AUTOSAR XML (schema 00046)
package /ComponentTypes
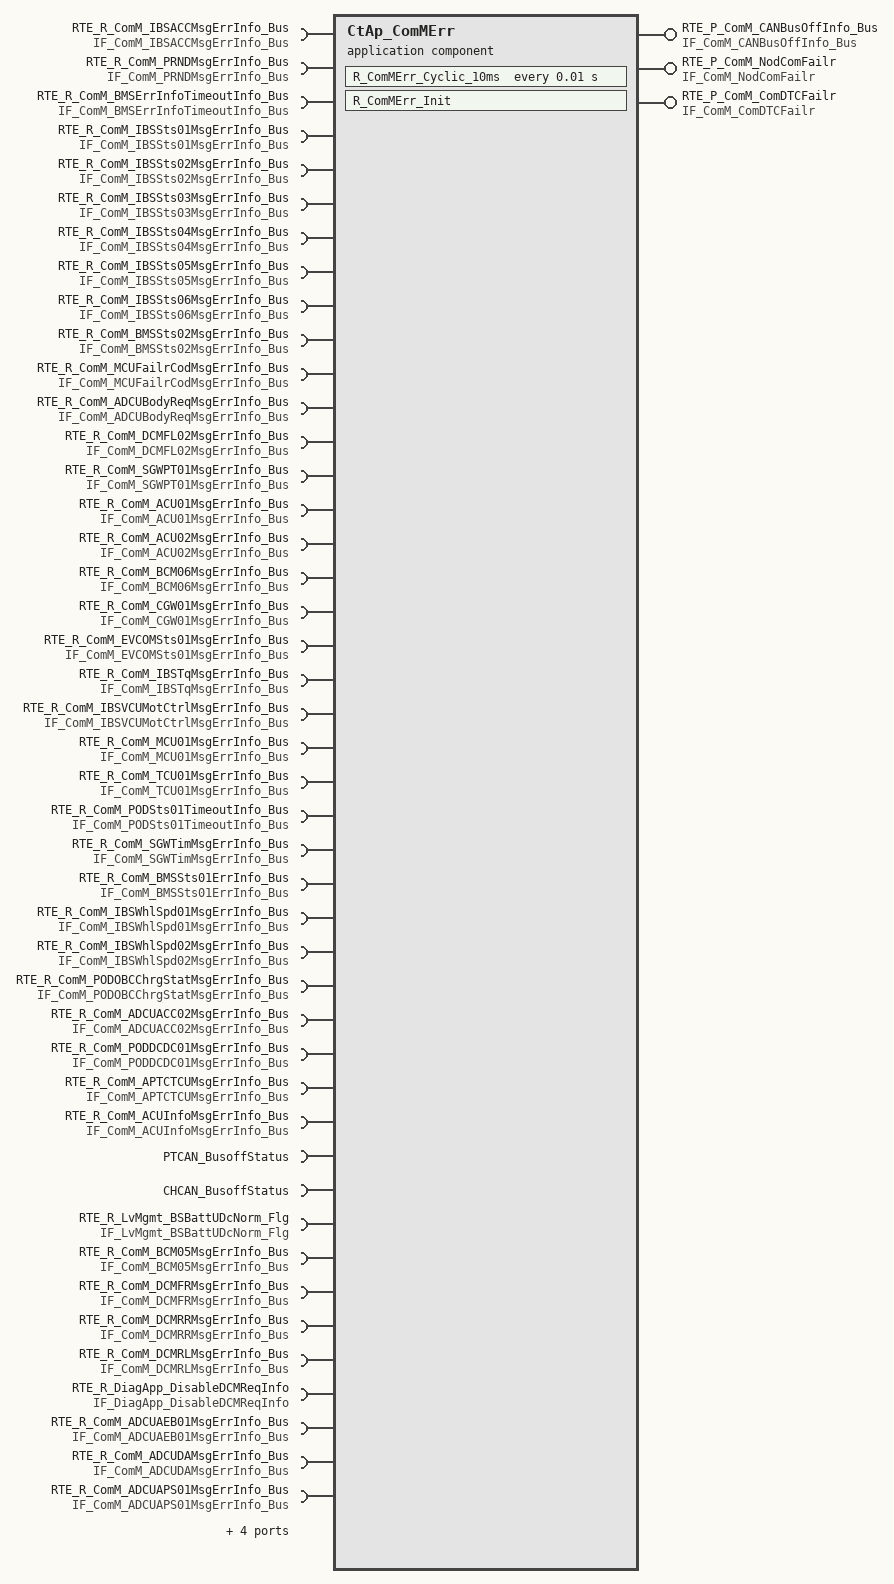
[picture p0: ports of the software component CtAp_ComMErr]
  application sw component type CtAp_ComMErr
    provide port RTE_P_ComM_CANBusOffInfo_Bus: provided-interface=IF_ComM_CANBusOffInfo_Bus
      provided-com-specs:
        data-element=tec_ComM_EPTCANBusOffInfo_Bus, init-value=fields=[ComM_MonStatEPTCANBusOffInfo:0, ComM_MonResEPTCANBusOffInfo:0, ComM_ErrStatEPTCANBusOffInfo:0, ComM_ErrResEPTCANBusOffInfo:0]
        data-element=tec_ComM_CHCANBusOffInfo_Bus, init-value=fields=[ComM_MonStatCHCANBusOffInfo:0, ComM_MonResCHCANBusOffInfo:0, ComM_ErrStatCHCANBusOffInfo:0, ComM_ErrResCHCANBusOffInfo:0]
        data-element=tec_ComM_EPTCANBusOffDTCInfo_Bus, init-value=fields=[ComM_MonStatEPTCANBusOffDTCInfo:0, ComM_MonResEPTCANBusOffDTCInfo:0, ComM_ErrStatEPTCANBusOffDTCInfo:0, ComM_ErrResEPTCANBusOffDTCInfo:0]
        data-element=tec_ComM_CHCANBusOffDTCInfo_Bus, init-value=fields=[ComM_MonStatCHCANBusOffDTCInfo:0, ComM_MonResCHCANBusOffDTCInfo:0, ComM_ErrStatCHCANBusOffDTCInfo:0, ComM_ErrResCHCANBusOffDTCInfo:0]
        data-element=tec_ComM_DCCANBusOffDTCInfo_Bus, init-value=fields=[ComM_MonStatDCCANDTCBusOffInfo:0, ComM_MonResDCCANDTCBusOffInfo:0, ComM_ErrStatDCCANDTCBusOffInfo:0, ComM_ErrResDCCANDTCBusOffInfo:0]
        data-element=tec_ComM_DCCANBusOffInfo_Bus, init-value=fields=[ComM_MonStatDCCANBusOffInfo:0, ComM_MonResDCCANBusOffInfo:0, ComM_ErrStatDCCANBusOffInfo:0, ComM_ErrResDCCANBusOffInfo:0]
    32 x require port:
      RTE_R_ComM_IBSACCMsgErrInfo_Bus: required-interface=IF_ComM_IBSACCMsgErrInfo_Bus
        required-com-specs:
          data-element=tec_ComM_IBSACCCRCDTCInfo_Bus, filter=data-filter-type=ALWAYS, init-value=fields=[ComM_MonStatIBSACCCRCDTCErrorInfo:0, ComM_MonResIBSACCCRCDTCErrorInfo:0, ComM_ErrStatIBSACCCRCDTCErrorInfo:0, ComM_ErrResIBSACCCRCDTCErrorInfo:0]
          data-element=tec_ComM_IBSACCCRCInfo_Bus, filter=data-filter-type=ALWAYS, init-value=fields=[ComM_MonStatIBSACCCRCErrorInfo:0, ComM_MonResIBSACCCRCErrorInfo:0, ComM_ErrStatIBSACCCRCErrorInfo:0, ComM_ErrResIBSACCCRCErrorInfo:0]
          data-element=tec_ComM_IBSACCTimeoutDTCInfo_Bus, filter=data-filter-type=ALWAYS, init-value=fields=[ComM_MonStatIBSACCTimeoutDTCErrorInfo:0, ComM_MonResIBSACCTimeoutDTCErrorInfo:0, ComM_ErrStatIBSACCTimeoutDTCErrorInfo:0, ComM_ErrResIBSACCTimeoutDTCErrorInfo:0]
          data-element=tec_ComM_IBSACCE2ETimeoutInfo_Bus, filter=data-filter-type=ALWAYS, init-value=fields=[ComM_MonStatIBSACCE2ETimeoutInfo:0, ComM_MonResIBSACCE2ETimeoutInfo:0, ComM_ErrStatIBSACCE2ETimeoutInfo:0, ComM_ErrResIBSACCE2ETimeoutInfo:0]
      RTE_R_ComM_PRNDMsgErrInfo_Bus: required-interface=IF_ComM_PRNDMsgErrInfo_Bus
        required-com-specs:
          data-element=tec_ComM_PRNDTimeoutInfo_Bus, filter=data-filter-type=ALWAYS, init-value=fields=[ComM_MonStatPRNDTimeoutInfo:0, ComM_MonResPRNDTimeoutInfo:0, ComM_ErrStatPRNDTimeoutInfo:0, ComM_ErrResPRNDTimeoutInfo:0]
          data-element=tec_ComM_PRNDCRCDTCInfo_Bus, filter=data-filter-type=ALWAYS, init-value=fields=[ComM_MonStatPRNDCRCDTCErrorInfo:0, ComM_MonResPRNDCRCDTCErrorInfo:0, ComM_ErrStatPRNDCRCDTCErrorInfo:0, ComM_ErrResPRNDCRCDTCErrorInfo:0]
          data-element=tec_ComM_PRNDCRCInfo_Bus, filter=data-filter-type=ALWAYS, init-value=fields=[ComM_MonStatPRNDCRCErrorInfo:0, ComM_MonResPRNDCRCErrorInfo:0, ComM_ErrStatPRNDCRCErrorInfo:0, ComM_ErrResPRNDCRCErrorInfo:0]
          data-element=tec_ComM_PRNDTimeoutDTCInfo_Bus, filter=data-filter-type=ALWAYS, init-value=fields=[ComM_MonStatPRNDTimeoutDTCErrorInfo:0, ComM_MonResPRNDTimeoutDTCErrorInfo:0, ComM_ErrStatPRNDTimeoutDTCErrorInfo:0, ComM_ErrResPRNDTimeoutDTCErrorInfo:0]
          data-element=tec_ComM_PRNDE2ETimeoutInfo_Bus, filter=data-filter-type=ALWAYS, init-value=fields=[ComM_MonStatPRNDE2ETimeoutInfo:0, ComM_MonResPRNDE2ETimeoutInfo:0, ComM_ErrStatPRNDE2ETimeoutInfo:0, ComM_ErrResPRNDE2ETimeoutInfo:0]
      RTE_R_ComM_BMSErrInfoTimeoutInfo_Bus: nonqueued-receiver-com-spec{data-element=tec_ComM_BMSErrInfoTimeoutInfo_Bus, filter=data-filter-type=ALWAYS, init-value=fields=[ComM_MonStatBMSErrInfoTimeoutInfo:0, ComM_MonResBMSErrInfoTimeoutInfo:0, ComM_ErrStatBMSErrInfoTimeoutInfo:0, ComM_ErrResBMSErrInfoTimeoutInfo:0]}, required-interface=IF_ComM_BMSErrInfoTimeoutInfo_Bus
      RTE_R_ComM_IBSSts01MsgErrInfo_Bus: required-interface=IF_ComM_IBSSts01MsgErrInfo_Bus
        required-com-specs:
          data-element=tec_ComM_IBSSts01CRCDTCInfo_Bus, filter=data-filter-type=ALWAYS, init-value=fields=[ComM_MonStatIBSSts01CRCDTCErrorInfo:0, ComM_MonResIBSSts01CRCDTCErrorInfo:0, ComM_ErrStatIBSSts01CRCDTCErrorInfo:0, ComM_ErrResIBSSts01CRCDTCErrorInfo:0]
          data-element=tec_ComM_IBSSts01TimeoutDTCInfo_Bus, filter=data-filter-type=ALWAYS, init-value=fields=[ComM_MonStatIBSSts01TimeoutDTCErrorInfo:0, ComM_MonResIBSSts01TimeoutDTCErrorInfo:0, ComM_ErrStatIBSSts01TimeoutDTCErrorInfo:0, ComM_ErrResIBSSts01TimeoutDTCErrorInfo:0]
          data-element=tec_ComM_IBSSts01CRCInfo_Bus, filter=data-filter-type=ALWAYS, init-value=fields=[ComM_MonStatIBSSts01CRCErrorInfo:0, ComM_MonResIBSSts01CRCErrorInfo:0, ComM_ErrStatIBSSts01CRCErrorInfo:0, ComM_ErrResIBSSts01CRCErrorInfo:0]
          data-element=tec_ComM_IBSSts01E2ETimeoutInfo_Bus, filter=data-filter-type=ALWAYS, init-value=fields=[ComM_MonStatIBSSts01E2ETimeoutInfo:0, ComM_MonResIBSSts01E2ETimeoutInfo:0, ComM_ErrStatIBSSts01E2ETimeoutInfo:0, ComM_ErrResIBSSts01E2ETimeoutInfo:0]
      RTE_R_ComM_IBSSts02MsgErrInfo_Bus: required-interface=IF_ComM_IBSSts02MsgErrInfo_Bus
        required-com-specs:
          data-element=tec_ComM_IBSSts02CRCInfo_Bus, filter=data-filter-type=ALWAYS, init-value=fields=[ComM_MonStatIBSSts02CRCErrorInfo:0, ComM_MonResIBSSts02CRCErrorInfo:0, ComM_ErrStatIBSSts02CRCErrorInfo:0, ComM_ErrResIBSSts02CRCErrorInfo:0]
          data-element=tec_ComM_IBSSts02CRCDTCInfo_Bus, filter=data-filter-type=ALWAYS, init-value=fields=[ComM_MonStatIBSSts02CRCDTCErrorInfo:0, ComM_MonResIBSSts02CRCDTCErrorInfo:0, ComM_ErrStatIBSSts02CRCDTCErrorInfo:0, ComM_ErrResIBSSts02CRCDTCErrorInfo:0]
          data-element=tec_ComM_IBSSts02TimeoutDTCInfo_Bus, filter=data-filter-type=ALWAYS, init-value=fields=[ComM_MonStatIBSSts02TimeoutDTCErrorInfo:0, ComM_MonResIBSSts02TimeoutDTCErrorInfo:0, ComM_ErrStatIBSSts02TimeoutDTCErrorInfo:0, ComM_ErrResIBSSts02TimeoutDTCErrorInfo:0]
          data-element=tec_ComM_IBSSts02E2ETimeoutInfo_Bus, filter=data-filter-type=ALWAYS, init-value=fields=[ComM_MonStatIBSSts02E2ETimeoutInfo:0, ComM_MonResIBSSts02E2ETimeoutInfo:0, ComM_ErrStatIBSSts02E2ETimeoutInfo:0, ComM_ErrResIBSSts02E2ETimeoutInfo:0]
      RTE_R_ComM_IBSSts03MsgErrInfo_Bus: required-interface=IF_ComM_IBSSts03MsgErrInfo_Bus
        required-com-specs:
          data-element=tec_ComM_IBSSts03CRCInfo_Bus, filter=data-filter-type=ALWAYS, init-value=fields=[ComM_MonStatIBSSts03CRCErrorInfo:0, ComM_MonResIBSSts03CRCErrorInfo:0, ComM_ErrStatIBSSts03CRCErrorInfo:0, ComM_ErrResIBSSts03CRCErrorInfo:0]
          data-element=tec_ComM_IBSSts03CRCDTCInfo_Bus, filter=data-filter-type=ALWAYS, init-value=fields=[ComM_MonStatIBSSts03CRCDTCErrorInfo:0, ComM_MonResIBSSts03CRCDTCErrorInfo:0, ComM_ErrStatIBSSts03CRCDTCErrorInfo:0, ComM_ErrResIBSSts03CRCDTCErrorInfo:0]
          data-element=tec_ComM_IBSSts03TimeoutDTCInfo_Bus, filter=data-filter-type=ALWAYS, init-value=fields=[ComM_MonStatIBSSts03TimeoutDTCErrorInfo:0, ComM_MonResIBSSts03TimeoutDTCErrorInfo:0, ComM_ErrStatIBSSts03TimeoutDTCErrorInfo:0, ComM_ErrResIBSSts03TimeoutDTCErrorInfo:0]
          data-element=tec_ComM_IBSSts03E2ETimeoutInfo_Bus, filter=data-filter-type=ALWAYS, init-value=fields=[ComM_MonStatIBSSts03E2ETimeoutInfo:0, ComM_MonResIBSSts03E2ETimeoutInfo:0, ComM_ErrStatIBSSts03E2ETimeoutInfo:0, ComM_ErrResIBSSts03E2ETimeoutInfo:0]
      RTE_R_ComM_IBSSts04MsgErrInfo_Bus: required-interface=IF_ComM_IBSSts04MsgErrInfo_Bus
        required-com-specs:
          data-element=tec_ComM_IBSSts04CRCDTCInfo_Bus, filter=data-filter-type=ALWAYS, init-value=fields=[ComM_MonStatIBSSts04CRCDTCErrorInfo:0, ComM_MonResIBSSts04CRCDTCErrorInfo:0, ComM_ErrStatIBSSts04CRCDTCErrorInfo:0, ComM_ErrResIBSSts04CRCDTCErrorInfo:0]
          data-element=tec_ComM_IBSSts04CRCInfo_Bus, filter=data-filter-type=ALWAYS, init-value=fields=[ComM_MonStatIBSSts04CRCErrorInfo:0, ComM_MonResIBSSts04CRCErrorInfo:0, ComM_ErrStatIBSSts04CRCErrorInfo:0, ComM_ErrResIBSSts04CRCErrorInfo:0]
          data-element=tec_ComM_IBSSts04TimeoutDTCInfo_Bus, filter=data-filter-type=ALWAYS, init-value=fields=[ComM_MonStatIBSSts04TimeoutDTCErrorInfo:0, ComM_MonResIBSSts04TimeoutDTCErrorInfo:0, ComM_ErrStatIBSSts04TimeoutDTCErrorInfo:0, ComM_ErrResIBSSts04TimeoutDTCErrorInfo:0]
          data-element=tec_ComM_IBSSts04E2ETimeoutInfo_Bus, filter=data-filter-type=ALWAYS, init-value=fields=[ComM_MonStatIBSSts04E2ETimeoutInfo:0, ComM_MonResIBSSts04E2ETimeoutInfo:0, ComM_ErrStatIBSSts04E2ETimeoutInfo:0, ComM_ErrResIBSSts04E2ETimeoutInfo:0]
      RTE_R_ComM_IBSSts05MsgErrInfo_Bus: required-interface=IF_ComM_IBSSts05MsgErrInfo_Bus
        required-com-specs:
          data-element=tec_ComM_IBSSts05CRCDTCInfo_Bus, filter=data-filter-type=ALWAYS, init-value=fields=[ComM_MonStatIBSSts05CRCDTCErrorInfo:0, ComM_MonResIBSSts05CRCDTCErrorInfo:0, ComM_ErrStatIBSSts05CRCDTCErrorInfo:0, ComM_ErrResIBSSts05CRCDTCErrorInfo:0]
          data-element=tec_ComM_IBSSts05TimeoutDTCInfo_Bus, filter=data-filter-type=ALWAYS, init-value=fields=[ComM_MonStatIBSSts05TimeoutDTCErrorInfo:0, ComM_MonResIBSSts05TimeoutDTCErrorInfo:0, ComM_ErrStatIBSSts05TimeoutDTCErrorInfo:0, ComM_ErrResIBSSts05TimeoutDTCErrorInfo:0]
          data-element=tec_ComM_IBSSts05TimeoutInfo_Bus, filter=data-filter-type=ALWAYS, init-value=fields=[ComM_MonStatIBSSts05TimeoutInfo:0, ComM_MonResIBSSts05TimeoutInfo:0, ComM_ErrStatIBSSts05TimeoutInfo:0, ComM_ErrResIBSSts05TimeoutInfo:0]
          data-element=tec_ComM_IBSSts05CRCInfo_Bus, init-value=fields=[ComM_MonStatIBSSts05CRCErrorInfo:0, ComM_MonResIBSSts05CRCErrorInfo:0, ComM_ErrStatIBSSts05CRCErrorInfo:0, ComM_ErrResIBSSts05CRCErrorInfo:0]
          data-element=tec_ComM_IBSSts05E2ETimeoutInfo_Bus, init-value=fields=[ComM_MonStatIBSSts05E2ETimeoutInfo:0, ComM_MonResIBSSts05E2ETimeoutInfo:0, ComM_ErrStatIBSSts05E2ETimeoutInfo:0, ComM_ErrResIBSSts05E2ETimeoutInfo:0]
      RTE_R_ComM_IBSSts06MsgErrInfo_Bus: required-interface=IF_ComM_IBSSts06MsgErrInfo_Bus
        required-com-specs:
          data-element=tec_ComM_IBSSts06CRCDTCInfo_Bus, filter=data-filter-type=ALWAYS, init-value=fields=[ComM_MonStatIBSSts06CRCDTCErrorInfo:0, ComM_MonResIBSSts06CRCDTCErrorInfo:0, ComM_ErrStatIBSSts06CRCDTCErrorInfo:0, ComM_ErrResIBSSts06CRCDTCErrorInfo:0]
          data-element=tec_ComM_IBSSts06TimeoutDTCInfo_Bus, filter=data-filter-type=ALWAYS, init-value=fields=[ComM_MonStatIBSSts06TimeoutDTCErrorInfo:0, ComM_MonResIBSSts06TimeoutDTCErrorInfo:0, ComM_ErrStatIBSSts06TimeoutDTCErrorInfo:0, ComM_ErrResIBSSts06TimeoutDTCErrorInfo:0]
      RTE_R_ComM_BMSSts02MsgErrInfo_Bus: required-interface=IF_ComM_BMSSts02MsgErrInfo_Bus
        required-com-specs:
          data-element=tec_ComM_BMSSts02TimeoutDTCInfo_Bus, filter=data-filter-type=ALWAYS, init-value=fields=[ComM_MonStatBMSSts02TimeoutDTCErrorInfo:0, ComM_MonResBMSSts02TimeoutDTCErrorInfo:0, ComM_ErrStatBMSSts02TimeoutDTCErrorInfo:0, ComM_ErrResBMSSts02TimeoutDTCErrorInfo:0]
          data-element=tec_ComM_BMSSts02TimeoutInfo_Bus, filter=data-filter-type=ALWAYS, init-value=fields=[ComM_MonStatBMSSts02TimeoutInfo:0, ComM_MonResBMSSts02TimeoutInfo:0, ComM_ErrStatBMSSts02TimeoutInfo:0, ComM_ErrResBMSSts02TimeoutInfo:0]
      RTE_R_ComM_MCUFailrCodMsgErrInfo_Bus: required-interface=IF_ComM_MCUFailrCodMsgErrInfo_Bus
        required-com-specs:
          data-element=tec_ComM_MCUFailrCodCRCDTCInfo_Bus, filter=data-filter-type=ALWAYS, init-value=fields=[ComM_MonStatMCUFailrCodCRCDTCErrorInfo:0, ComM_MonResMCUFailrCodCRCDTCErrorInfo:0, ComM_ErrStatMCUFailrCodCRCDTCErrorInfo:0, ComM_ErrResMCUFailrCodCRCDTCErrorInfo:0]
          data-element=tec_ComM_MCUFailrCodTimeoutDTCInfo_Bus, filter=data-filter-type=ALWAYS, init-value=fields=[ComM_MonStatMCUFailrCodTimeoutDTCErrorInfo:0, ComM_MonResMCUFailrCodTimeoutDTCErrorInfo:0, ComM_ErrStatMCUFailrCodTimeoutDTCErrorInfo:0, ComM_ErrResMCUFailrCodTimeoutDTCErrorInfo:0]
          data-element=tec_ComM_MCUFailrCodCRCInfo_Bus, init-value=fields=[ComM_MonStatMCUFailrCodCRCErrorInfo:0, ComM_MonResMCUFailrCodCRCErrorInfo:0, ComM_ErrStatMCUFailrCodCRCErrorInfo:0, ComM_ErrResMCUFailrCodCRCErrorInfo:0]
          data-element=tec_ComM_MCUFailrCodE2ETimeoutInfo_Bus, init-value=fields=[ComM_MonStatMCUFailrCodE2ETimeouInfo:0, ComM_MonResMCUFailrCodE2ETimeoutInfo:0, ComM_ErrStatMCUFailrCodE2ETimeoutInfo:0, ComM_ErrResMCUFailrCodE2ETimeoutInfo:0]
      RTE_R_ComM_ADCUBodyReqMsgErrInfo_Bus: required-interface=IF_ComM_ADCUBodyReqMsgErrInfo_Bus
        required-com-specs:
          data-element=tec_ComM_ADCUBodyReqCRCDTCInfo_Bus, filter=data-filter-type=ALWAYS, init-value=fields=[ComM_MonStatADCUBodyReqCRCDTCErrorInfo:0, ComM_MonResADCUBodyReqCRCDTCErrorInfo:0, ComM_ErrStatADCUBodyReqCRCDTCErrorInfo:0, ComM_ErrResADCUBodyReqCRCDTCErrorInfo:0]
          data-element=tec_ComM_ADCUBodyReqTimeoutDTCInfo_Bus, filter=data-filter-type=ALWAYS, init-value=fields=[ComM_MonStatADCUBodyReqTimeoutDTCErrorInfo:0, ComM_MonResADCUBodyReqTimeoutDTCErrorInfo:0, ComM_ErrStatADCUBodyReqTimeoutDTCErrorInfo:0, ComM_ErrResADCUBodyReqTimeoutDTCErrorInfo:0]
      RTE_R_ComM_DCMFL02MsgErrInfo_Bus: required-interface=IF_ComM_DCMFL02MsgErrInfo_Bus
        required-com-specs:
          data-element=tec_ComM_DCMFL02CRCDTCInfo_Bus, filter=data-filter-type=ALWAYS, init-value=fields=[ComM_MonStatDCMFL02CRCDTCErrorInfo:0, ComM_MonResDCMFL02CRCDTCErrorInfo:0, ComM_ErrStatDCMFL02CRCDTCErrorInfo:0, ComM_ErrResDCMFL02CRCDTCErrorInfo:0]
          data-element=tec_ComM_DCMFL02TimeoutDTCInfo_Bus, filter=data-filter-type=ALWAYS, init-value=fields=[ComM_MonStatDCMFL02TimeoutDTCErrorInfo:0, ComM_MonResDCMFL02TimeoutDTCErrorInfo:0, ComM_ErrStatDCMFL02TimeoutDTCErrorInfo:0, ComM_ErrResDCMFL02TimeoutDTCErrorInfo:0]
          data-element=tec_ComM_DCMFL02TimeoutInfo_Bus, filter=data-filter-type=ALWAYS, init-value=fields=[ComM_MonStatDCMFL02TimeoutInfo:0, ComM_MonResDCMFL02TimeoutInfo:0, ComM_ErrStatDCMFL02TimeoutInfo:0, ComM_ErrResDCMFL02TimeoutInfo:0]
      RTE_R_ComM_SGWPT01MsgErrInfo_Bus: required-interface=IF_ComM_SGWPT01MsgErrInfo_Bus
        required-com-specs:
          data-element=tec_ComM_SGWPT01TimeoutDTCInfo_Bus, filter=data-filter-type=ALWAYS, init-value=fields=[ComM_MonStatSGWPT01TimeoutDTCErrorInfo:0, ComM_MonResSGWPT01TimeoutDTCErrorInfo:0, ComM_ErrStatSGWPT01TimeoutDTCErrorInfo:0, ComM_ErrResSGWPT01TimeoutDTCErrorInfo:0]
          data-element=tec_ComM_SGWPT01TimeoutInfo_Bus, filter=data-filter-type=ALWAYS, init-value=fields=[ComM_MonStatSGWPT01TimeoutInfo:0, ComM_MonResSGWPT01TimeoutInfo:0, ComM_ErrStatSGWPT01TimeoutInfo:0, ComM_ErrResSGWPT01TimeoutInfo:0]
      RTE_R_ComM_ACU01MsgErrInfo_Bus: required-interface=IF_ComM_ACU01MsgErrInfo_Bus
        required-com-specs:
          data-element=tec_ComM_ACU01CRCDTCInfo_Bus, filter=data-filter-type=ALWAYS, init-value=fields=[ComM_MonStatACU01CRCDTCErrorInfo:0, ComM_MonResACU01CRCDTCErrorInfo:0, ComM_ErrStatACU01CRCDTCErrorInfo:0, ComM_ErrResACU01CRCDTCErrorInfo:0]
          data-element=tec_ComM_ACU01TimeoutDTCInfo_Bus, filter=data-filter-type=ALWAYS, init-value=fields=[ComM_MonStatACU01TimeoutDTCInfo:0, ComM_MonResACU01TimeoutDTCInfo:0, ComM_ErrStatACU01TimeoutDTCInfo:0, ComM_ErrResACU01TimeoutDTCInfo:0]
      RTE_R_ComM_ACU02MsgErrInfo_Bus: required-interface=IF_ComM_ACU02MsgErrInfo_Bus
        required-com-specs:
          data-element=tec_ComM_ACU02CRCDTCInfo_Bus, filter=data-filter-type=ALWAYS, init-value=fields=[ComM_MonStatACU02CRCDTCErrorInfo:0, ComM_MonResACU02CRCDTCErrorInfo:0, ComM_ErrStatACU02CRCDTCErrorInfo:0, ComM_ErrResACU02CRCDTCErrorInfo:0]
          data-element=tec_ComM_ACU02TimeoutDTCInfo_Bus, filter=data-filter-type=ALWAYS, init-value=fields=[ComM_MonStatACU02TimeoutDTCInfo:0, ComM_MonResACU02TimeoutDTCInfo:0, ComM_ErrStatACU02TimeoutDTCInfo:0, ComM_ErrResACU02TimeoutDTCInfo:0]
          data-element=tec_ComM_ACU02TimeoutInfo_Bus
      RTE_R_ComM_BCM06MsgErrInfo_Bus: required-interface=IF_ComM_BCM06MsgErrInfo_Bus
        required-com-specs:
          data-element=tec_ComM_BCM06CRCDTCInfo_Bus, filter=data-filter-type=ALWAYS, init-value=fields=[ComM_MonStatBCM06CRCDTCErrorInfo:0, ComM_MonResBCM06CRCDTCErrorInfo:0, ComM_ErrStatBCM06CRCDTCErrorInfo:0, ComM_ErrResBCM06CRCDTCErrorInfo:0]
          data-element=tec_ComM_BCM06TimeoutDTCInfo_Bus, filter=data-filter-type=ALWAYS, init-value=fields=[ComM_MonStatBCM06TimeoutDTCErrorInfo:0, ComM_MonResBCM06TimeoutDTCErrorInfo:0, ComM_ErrStatBCM06TimeoutDTCErrorInfo:0, ComM_ErrResBCM06TimeoutDTCErrorInfo:0]
          data-element=tec_ComM_BCM06TimeoutInfo_Bus, filter=data-filter-type=ALWAYS, init-value=fields=[ComM_MonStatBCM06TimeoutInfo:0, ComM_MonResBCM06TimeoutInfo:0, ComM_ErrStatBCM06TimeoutInfo:0, ComM_ErrResBCM06TimeoutInfo:0]
      RTE_R_ComM_CGW01MsgErrInfo_Bus: required-interface=IF_ComM_CGW01MsgErrInfo_Bus
        required-com-specs:
          data-element=tec_ComM_CGW01TimeoutDTCInfo_Bus, filter=data-filter-type=ALWAYS, init-value=fields=[ComM_MonStatCGW01TimeoutDTCErrorInfo:0, ComM_MonResCGW01TimeoutDTCErrorInfo:0, ComM_ErrStatCGW01TimeoutDTCErrorInfo:0, ComM_ErrResCGW01TimeoutDTCErrorInfo:0]
          data-element=tec_ComM_CGW01TimeoutInfo_Bus, filter=data-filter-type=ALWAYS, init-value=fields=[ComM_MonStatCGW01TimeoutInfo:0, ComM_MonResCGW01TimeoutInfo:0, ComM_ErrStatCGW01TimeoutInfo:0, ComM_ErrResCGW01TimeoutInfo:0]
          data-element=tec_ComM_CGW01CRCDTCInfo_Bus, init-value=fields=[ComM_MonStatCGW01CRCDTCErrorInfo:0, ComM_MonResCGW01CRCDTCErrorInfo:0, ComM_ErrStatCGW01CRCDTCErrorInfo:0, ComM_ErrResCGW01ACRCDTCErrorInfo:0]
      RTE_R_ComM_EVCOMSts01MsgErrInfo_Bus: required-interface=IF_ComM_EVCOMSts01MsgErrInfo_Bus
        required-com-specs:
          data-element=tec_ComM_EVCOMSts01TimeoutDTCInfo_Bus, filter=data-filter-type=ALWAYS, init-value=fields=[ComM_MonStatEVCOMSts01TimeoutDTCErrorInfo:0, ComM_MonResEVCOMSts01TimeoutDTCErrorInfo:0, ComM_ErrStatEVCOMSts01TimeoutDTCErrorInfo:0, ComM_ErrResEVCOMSts01TimeoutDTCErrorInfo:0]
          data-element=tec_ComM_EVCOMSts01TimeoutInfo_Bus, filter=data-filter-type=ALWAYS, init-value=fields=[ComM_MonStatEVCOMSts01TimeoutInfo:0, ComM_MonResEVCOMSts01TimeoutInfo:0, ComM_ErrStatEVCOMSts01TimeoutInfo:0, ComM_ErrResEVCOMSts01TimeoutInfo:0]
      RTE_R_ComM_IBSTqMsgErrInfo_Bus: required-interface=IF_ComM_IBSTqMsgErrInfo_Bus
        required-com-specs:
          data-element=tec_ComM_IBSTqCRCDTCInfo_Bus, filter=data-filter-type=ALWAYS, init-value=fields=[ComM_MonStatIBSTqCRCDTCErrorInfo:0, ComM_MonResIBSTqCRCDTCErrorInfo:0, ComM_ErrStatIBSTqCRCDTCErrorInfo:0, ComM_ErrResIBSTqCRCDTCErrorInfo:0]
          data-element=tec_ComM_IBSTqTimeoutDTCInfo_Bus, filter=data-filter-type=ALWAYS, init-value=fields=[ComM_MonStatIBSTqTimeoutDTCErrorInfo:0, ComM_MonResIBSTqTimeoutDTCErrorInfo:0, ComM_ErrStatIBSTqTimeoutDTCErrorInfo:0, ComM_ErrResIBSTqTimeoutDTCErrorInfo:0]
          data-element=tec_ComM_IBSTqCRCInfo_Bus, filter=data-filter-type=ALWAYS, init-value=fields=[ComM_MonStatIBSTqCRCErrorInfo:0, ComM_MonResIBSTqCRCErrorInfo:0, ComM_ErrStatIBSTqCRCErrorInfo:0, ComM_ErrResIBSTqCRCErrorInfo:0]
          data-element=tec_ComM_IBSTqE2ETimeoutInfo_Bus, filter=data-filter-type=ALWAYS, init-value=fields=[ComM_MonStatIBSTqE2ETimeoutInfo:0, ComM_MonResIBSTqE2ETimeoutInfo:0, ComM_ErrStatIBSTqE2ETimeoutInfo:0, ComM_ErrResIBSTqE2ETimeoutInfo:0]
      RTE_R_ComM_IBSVCUMotCtrlMsgErrInfo_Bus: required-interface=IF_ComM_IBSVCUMotCtrlMsgErrInfo_Bus
        required-com-specs:
          data-element=tec_ComM_IBSVCUMotCtrlCRCDTCInfo_Bus, filter=data-filter-type=ALWAYS, init-value=fields=[ComM_MonStatIBSVCUMotCtrlCRCDTCErrorInfo:0, ComM_MonResIBSVCUMotCtrlCRCDTCErrorInfo:0, ComM_ErrStatIBSVCUMotCtrlCRCDTCErrorInfo:0, ComM_ErrResIBSVCUMotCtrlCRCDTCErrorInfo:0]
          data-element=tec_ComM_IBSVCUMotCtrlTimeoutInfo_Bus, filter=data-filter-type=ALWAYS, init-value=fields=[ComM_MonStatIBSVCUMotCtrlTimeoutInfo:0, ComM_MonResIBSVCUMotCtrlTimeoutInfo:0, ComM_ErrStatIBSVCUMotCtrlTimeoutInfo:0, ComM_ErrResIBSVCUMotCtrlTimeoutInfo:0]
          data-element=tec_ComM_IBSVCUMotCtrlCRCInfo_Bus, filter=data-filter-type=ALWAYS, init-value=fields=[ComM_MonStatIBSVCUMotCtrlCRCErrorInfo:0, ComM_MonResIBSVCUMotCtrlCRCErrorInfo:0, ComM_ErrStatIBSVCUMotCtrlCRCErrorInfo:0, ComM_ErrResIBSVCUMotCtrlCRCErrorInfo:0]
          data-element=tec_ComM_IBSVCUMotCtrlTimeoutDTCInfo_Bus, filter=data-filter-type=ALWAYS, init-value=fields=[ComM_MonStatIBSVCUMotCtrlTimeoutDTCErrorInfo:0, ComM_MonResIBSVCUMotCtrlTimeoutDTCErrorInfo:0, ComM_ErrStatIBSVCUMotCtrlTimeoutDTCErrorInfo:0, ComM_ErrResIBSVCUMotCtrlTimeoutDTCErrorInfo:0]
          data-element=tec_ComM_IBSVCUMotCtrlE2ETimeoutInfo_Bus, filter=data-filter-type=ALWAYS, init-value=fields=[ComM_MonStatIBSVCUMotCtrlE2ETimeoutInfo:0, ComM_MonResIBSVCUMotCtrlE2ETimeoutInfo:0, ComM_ErrStatIBSVCUMotCtrlE2ETimeoutInfo:0, ComM_ErrResIBSVCUMotCtrlE2ETimeoutInfo:0]
      RTE_R_ComM_MCU01MsgErrInfo_Bus: required-interface=IF_ComM_MCU01MsgErrInfo_Bus
        required-com-specs:
          data-element=tec_ComM_MCU01TimeoutInfo_Bus, filter=data-filter-type=ALWAYS, init-value=fields=[ComM_MonStatMCU01TimeoutInfo:0, ComM_MonResMCU01TimeoutInfo:0, ComM_ErrStatMCU01TimeoutInfo:0, ComM_ErrResMCU01TimeoutInfo:0]
          data-element=tec_ComM_MCU01CRCDTCInfo_Bus, filter=data-filter-type=ALWAYS, init-value=fields=[ComM_MonStatMCU01CRCDTCErrorInfo:0, ComM_MonResMCU01CRCDTCErrorInfo:0, ComM_ErrStatMCU01CRCDTCErrorInfo:0, ComM_ErrResMCU01CRCDTCErrorInfo:0]
          data-element=tec_ComM_MCU01CRCInfo_Bus, filter=data-filter-type=ALWAYS, init-value=fields=[ComM_MonStatMCU01CRCErrorInfo:0, ComM_MonResMCU01CRCErrorInfo:0, ComM_ErrStatMCU01CRCErrorInfo:0, ComM_ErrResMCU01CRCErrorInfo:0]
          data-element=tec_ComM_MCU01TimeoutDTCInfo_Bus, filter=data-filter-type=ALWAYS, init-value=fields=[ComM_MonStatMCU01TimeoutDTCErrorInfo:0, ComM_MonResMCU01TimeoutDTCErrorInfo:0, ComM_ErrStatMCU01TimeoutDTCErrorInfo:0, ComM_ErrResMCU01TimeoutDTCErrorInfo:0]
          data-element=tec_ComM_MCU01E2ETimeoutInfo_Bus, filter=data-filter-type=ALWAYS, init-value=fields=[ComM_MonStatMCU01E2ETimeoutInfo:0, ComM_MonResMCU01E2ETimeoutInfo:0, ComM_ErrStatMCU01E2ETimeoutInfo:0, ComM_ErrResMCU01E2ETimeoutInfo:0]
      RTE_R_ComM_TCU01MsgErrInfo_Bus: required-interface=IF_ComM_TCU01MsgErrInfo_Bus
        required-com-specs:
          data-element=tec_ComM_TCU01TimeoutDTCInfo_Bus, filter=data-filter-type=ALWAYS, init-value=fields=[ComM_MonStatTCU01TimeoutDTCErrorInfo:0, ComM_MonResTCU01TimeoutDTCErrorInfo:0, ComM_ErrStatTCU01TimeoutDTCErrorInfo:0, ComM_ErrResTCU01TimeoutDTCErrorInfo:0]
          data-element=tec_ComM_TCU01TimeoutInfo_Bus, filter=data-filter-type=ALWAYS, init-value=fields=[ComM_MonStatTCU01TimeoutInfo:0, ComM_MonResTCU01TimeoutInfo:0, ComM_ErrStatTCU01TimeoutInfo:0, ComM_ErrResTCU01TimeoutInfo:0]
      RTE_R_ComM_PODSts01TimeoutInfo_Bus: nonqueued-receiver-com-spec{data-element=tec_ComM_PODSts01TimeoutInfo_Bus, filter=data-filter-type=ALWAYS, init-value=fields=[ComM_MonStatPODSts01TimeoutInfo:0, ComM_MonResPODSts01TimeoutInfo:0, ComM_ErrStatPODSts01TimeoutInfo:0, ComM_ErrResPODSts01TimeoutInfo:0]}, required-interface=IF_ComM_PODSts01TimeoutInfo_Bus
      RTE_R_ComM_SGWTimMsgErrInfo_Bus: required-interface=IF_ComM_SGWTimMsgErrInfo_Bus
        required-com-specs:
          data-element=tec_ComM_SGWTimTimeoutDTCInfo_Bus, filter=data-filter-type=ALWAYS, init-value=fields=[ComM_MonStatSGWTimTimeoutDTCErrorInfo:0, ComM_MonResSGWTimTimeoutDTCErrorInfo:0, ComM_ErrStatSGWTimTimeoutDTCErrorInfo:0, ComM_ErrResSGWTimTimeoutDTCErrorInfo:0]
          data-element=tec_ComM_SGWTimTimeoutInfo_Bus, filter=data-filter-type=ALWAYS, init-value=fields=[ComM_MonStatSGWTimTimeoutInfo:0, ComM_MonResSGWTimTimeoutInfo:0, ComM_ErrStatSGWTimTimeoutInfo:0, ComM_ErrResSGWTimTimeoutInfo:0]
      RTE_R_ComM_BMSSts01ErrInfo_Bus: required-interface=IF_ComM_BMSSts01ErrInfo_Bus
        required-com-specs:
          data-element=tec_ComM_BMSSts01TimeoutInfo_Bus, filter=data-filter-type=ALWAYS, init-value=fields=[ComM_MonStatBMSSts01TimeoutInfo:0, ComM_MonResBMSSts01TimeoutInfo:0, ComM_ErrStatBMSSts01TimeoutInfo:0, ComM_ErrResBMSSts01TimeoutInfo:0]
          data-element=tec_ComM_BMSSts01CRCDTCInfo_Bus, filter=data-filter-type=ALWAYS, init-value=fields=[ComM_MonStatBMSSts01CRCDTCErrorInfo:0, ComM_MonResBMSSts01CRCDTCErrorInfo:0, ComM_ErrStatBMSSts01CRCDTCErrorInfo:0, ComM_ErrResBMSSts01CRCDTCErrorInfo:0]
          data-element=tec_ComM_BMSSts01CRCInfo_Bus, filter=data-filter-type=ALWAYS, init-value=fields=[ComM_MonStatBMSSts01CRCErrorInfo:0, ComM_MonResBMSSts01CRCErrorInfo:0, ComM_ErrStatBMSSts01CRCErrorInfo:0, ComM_ErrResBMSSts01CRCErrorInfo:0]
          data-element=tec_ComM_BMSSts01TimeoutDTCInfo_Bus, filter=data-filter-type=ALWAYS, init-value=fields=[ComM_MonStatBMSSts01TimeoutDTCErrorInfo:0, ComM_MonResBMSSts01TimeoutDTCErrorInfo:0, ComM_ErrStatBMSSts01TimeoutDTCErrorInfo:0, ComM_ErrResBMSSts01TimeoutDTCErrorInfo:0]
          data-element=tec_ComM_BMSSts01E2ETimeoutInfo_Bus, filter=data-filter-type=ALWAYS, init-value=fields=[ComM_MonStatBMSSts01E2ETimeoutInfo:0, ComM_MonResBMSSts01E2ETimeoutInfo:0, ComM_ErrStatBMSSts01E2ETimeoutInfo:0, ComM_ErrResBMSSts01E2ETimeoutInfo:0]
      RTE_R_ComM_IBSWhlSpd01MsgErrInfo_Bus: required-interface=IF_ComM_IBSWhlSpd01MsgErrInfo_Bus
        required-com-specs:
          data-element=tec_ComM_IBSWhlSpd01CRCDTCInfo_Bus, filter=data-filter-type=ALWAYS, init-value=fields=[ComM_MonStatIBSWhlSpd01CRCDTCErrorInfo:0, ComM_MonResIBSWhlSpd01CRCDTCErrorInfo:0, ComM_ErrStatIBSWhlSpd01CRCDTCErrorInfo:0, ComM_ErrResIBSWhlSpd01CRCDTCErrorInfo:0]
          data-element=tec_ComM_IBSWhlSpd01TimeoutDTCInfo_Bus, filter=data-filter-type=ALWAYS, init-value=fields=[ComM_MonStatIBSWhlSpd01TimeoutInfo:0, ComM_MonResIBSWhlSpd01TimeoutInfo:0, ComM_ErrStatIBSWhlSpd01TimeoutInfo:0, ComM_ErrResIBSWhlSpd01TimeoutInfo:0]
      RTE_R_ComM_IBSWhlSpd02MsgErrInfo_Bus: required-interface=IF_ComM_IBSWhlSpd02MsgErrInfo_Bus
        required-com-specs:
          data-element=tec_ComM_IBSWhlSpd02CRCDTCInfo_Bus, filter=data-filter-type=ALWAYS, init-value=fields=[ComM_MonStatIBSWhlSpd02CRCDTCErrorInfo:0, ComM_MonResIBSWhlSpd02CRCDTCErrorInfo:0, ComM_ErrStatIBSWhlSpd02CRCDTCErrorInfo:0, ComM_ErrResIBSWhlSpd02CRCDTCErrorInfo:0]
          data-element=tec_ComM_IBSWhlSpd02TimeoutDTCInfo_Bus, filter=data-filter-type=ALWAYS, init-value=fields=[ComM_MonStatIBSWhlSpd02TimeoutInfo:0, ComM_MonResIBSWhlSpd02TimeoutInfo:0, ComM_ErrStatIBSWhlSpd02TimeoutInfo:0, ComM_ErrResIBSWhlSpd02TimeoutInfo:0]
      RTE_R_ComM_PODOBCChrgStatMsgErrInfo_Bus: required-interface=IF_ComM_PODOBCChrgStatMsgErrInfo_Bus
        required-com-specs:
          data-element=tec_ComM_PODOBCChrgStatTimeoutDTCInfo_Bus, filter=data-filter-type=ALWAYS, init-value=fields=[ComM_MonStatPODOBCChrgStatTimeoutDTCErrorInfo:0, ComM_MonResPODOBCChrgStatTimeoutDTCErrorInfo:0, ComM_ErrStatPODOBCChrgStatTimeoutDTCErrorInfo:0, ComM_ErrResPODOBCChrgStatTimeoutDTCErrorInfo:0]
          data-element=tec_ComM_PODOBCChrgStatTimeoutInfo_Bus, filter=data-filter-type=ALWAYS, init-value=fields=[ComM_MonStatPODOBCChrgStatTimeoutInfo:0, ComM_MonResPODOBCChrgStatTimeoutInfo:0, ComM_ErrStatPODOBCChrgStatTimeoutInfo:0, ComM_ErrResPODOBCChrgStatTimeoutInfo:0]
      RTE_R_ComM_ADCUACC02MsgErrInfo_Bus: required-interface=IF_ComM_ADCUACC02MsgErrInfo_Bus
        required-com-specs:
          data-element=tec_ComM_ADCUACC02CRCDTCInfo_Bus, filter=data-filter-type=ALWAYS, init-value=fields=[ComM_MonStatADCUACC02CRCDTCErrorInfo:0, ComM_MonResADCUACC02CRCDTCErrorInfo:0, ComM_ErrStatADCUACC02CRCDTCErrorInfo:0, ComM_ErrResADCUACC02CRCDTCErrorInfo:0]
          data-element=tec_ComM_ADCUACC02TimeoutDTCInfo_Bus, filter=data-filter-type=ALWAYS, init-value=fields=[ComM_MonStatADCUACC02TimeoutDTCErrorInfo:0, ComM_MonResADCUACC02TimeoutDTCErrorInfo:0, ComM_ErrStatADCUACC02TimeoutDTCErrorInfo:0, ComM_ErrResADCUACC02TimeoutDTCErrorInfo:0]
          data-element=tec_ComM_ADCUACC02TimeoutInfo_Bus, filter=data-filter-type=ALWAYS, init-value=fields=[ComM_MonStatADCUACC02TimeoutInfo:0, ComM_MonResADCUACC02TimeoutInfo:0, ComM_ErrStatADCUACC02TimeoutInfo:0, ComM_ErrResADCUACC02TimeoutInfo:0]
      RTE_R_ComM_PODDCDC01MsgErrInfo_Bus: required-interface=IF_ComM_PODDCDC01MsgErrInfo_Bus
        required-com-specs:
          data-element=tec_ComM_PODDCDC01TimeoutDTCInfo_Bus, filter=data-filter-type=ALWAYS, init-value=fields=[ComM_MonStatPODDCDC01TimeoutDTCErrorInfo:0, ComM_MonResPODDCDC01TimeoutDTCErrorInfo:0, ComM_ErrStatPODDCDC01TimeoutDTCErrorInfo:0, ComM_ErrResPODDCDC01TimeoutDTCErrorInfo:0]
          data-element=tec_ComM_PODDCDC01TimeoutInfo_Bus, filter=data-filter-type=ALWAYS, init-value=fields=[ComM_MonStatPODDCDC01TimeoutInfo:0, ComM_MonResPODDCDC01TimeoutInfo:0, ComM_ErrStatPODDCDC01TimeoutInfo:0, ComM_ErrResPODDCDC01TimeoutInfo:0]
      RTE_R_ComM_APTCTCUMsgErrInfo_Bus: required-interface=IF_ComM_APTCTCUMsgErrInfo_Bus
        required-com-specs:
          data-element=tec_ComM_APTCTCUTimeoutDTCInfo_Bus, filter=data-filter-type=ALWAYS, init-value=fields=[ComM_MonStatAPTCTCUTimeoutDTCErrorInfo:0, ComM_MonResAPTCTCUTimeoutDTCErrorInfo:0, ComM_ErrStatAPTCTCUTimeoutDTCErrorInfo:0, ComM_ErrResAPTCTCUTimeoutDTCErrorInfo:0]
          data-element=tec_ComM_APTCTCUTimeoutInfo_Bus, filter=data-filter-type=ALWAYS, init-value=fields=[ComM_MonStatAPTCTCUTimeoutInfo:0, ComM_MonResAPTCTCUTimeoutInfo:0, ComM_ErrStatAPTCTCUTimeoutInfo:0, ComM_ErrResAPTCTCUTimeoutInfo:0]
    provide port RTE_P_ComM_NodComFailr: provided-interface=IF_ComM_NodComFailr
      provided-com-specs:
        data-element=tec_ComM_SGWNodComFailr_Flg, init-value=0
        data-element=tec_ComM_CGWNodComFailr_Flg, init-value=0
        data-element=tec_ComM_TCUNodComFailr_Flg, init-value=0
        data-element=tec_ComM_BCMNodComFailr_Flg, init-value=0
        data-element=tec_ComM_PRNDNodComFailr_Flg, init-value=0
        data-element=tec_ComM_IVINodComFailr_Flg, init-value=0
        data-element=tec_ComM_DCDCNodComFailr_Flg, init-value=0
        data-element=tec_ComM_OBCNodComFailr_Flg, init-value=0
        data-element=tec_ComM_CHIBSNodComFailr_Flg, init-value=0
        data-element=tec_ComM_MCUNodComFailr_Flg, init-value=0
        data-element=tec_ComM_EVCOMNodComFailr_Flg, init-value=0
        data-element=tec_ComM_EPTIBSNodComFailr_Flg, init-value=0
        data-element=tec_ComM_DCMNodComFailr_Flg, init-value=0
        data-element=tec_ComM_BMSNodComFailr_Flg, init-value=0
        data-element=tec_ComM_ACUNodComFailr_Flg, init-value=0
        data-element=tec_ComM_APTCNodComFailr_Flg, init-value=0
        data-element=tec_ComM_ADCUNodComFailr_Flg, init-value=0
        data-element=tec_ComM_DCMRRNodComFailr_Flg, init-value=0
        data-element=tec_ComM_DCMRLNodComFailr_Flg, init-value=0
        data-element=tec_ComM_DCMFRNodComFailr_Flg, init-value=0
        data-element=tec_ComM_DCMFLNodComFailr_Flg, init-value=0
        data-element=tec_ComM_SGWCHNodComFailr_Flg, init-value=0
    provide port RTE_P_ComM_ComDTCFailr: provided-interface=IF_ComM_ComDTCFailr
      provided-com-specs:
        data-element=tec_ComM_EVCOMComDTCFailr_Flg, init-value=0
        data-element=tec_ComM_APTCComDTCFailr_Flg, init-value=0
        data-element=tec_ComM_CGWComDTCFailr_Flg, init-value=0
        data-element=tec_ComM_SGWComDTCFailr_Flg, init-value=0
        data-element=tec_ComM_BCMComDTCFailr_Flg, init-value=0
        data-element=tec_ComM_PRNDComDTCFailr_Flg, init-value=0
        data-element=tec_ComM_DCDCComDTCFailr_Flg, init-value=0
        data-element=tec_ComM_IVIComDTCFailr_Flg, init-value=0
        data-element=tec_ComM_BMSComDTCFailr_Flg, init-value=0
        data-element=tec_ComM_MCUComDTCFailr_Flg, init-value=0
        data-element=tec_ComM_TCUComDTCFailr_Flg, init-value=0
        data-element=tec_ComM_ADCUComDTCFailr_Flg, init-value=0
        data-element=tec_ComM_ACUComDTCFailr_Flg, init-value=0
        data-element=tec_ComM_CHIBSComDTCFailr_Flg, init-value=0
        data-element=tec_ComM_OBCComDTCFailr_Flg, init-value=0
        data-element=tec_ComM_EPTIBSComDTCFailr_Flg, init-value=0
        data-element=tec_ComM_SGWCHComDTCFailr_Flg, init-value=0
        data-element=tec_ComM_DCMRRComDTCFailr_Flg, init-value=0
        data-element=tec_ComM_DCMRLComDTCFailr_Flg, init-value=0
        data-element=tec_ComM_DCMFRComDTCFailr_Flg, init-value=0
        data-element=tec_ComM_DCMFLComDTCFailr_Flg, init-value=0
    16 x require port:
      RTE_R_ComM_ACUInfoMsgErrInfo_Bus: required-interface=IF_ComM_ACUInfoMsgErrInfo_Bus
        required-com-specs:
          data-element=tec_ComM_ACUInfoTimeoutDTCInfo_Bus, filter=data-filter-type=ALWAYS, init-value=fields=[ComM_MonStatACUInfoTimeoutDTCErrorInfo:0, ComM_MonResACUInfoTimeoutDTCErrorInfo:0, ComM_ErrStatACUInfoTimeoutDTCErrorInfo:0, ComM_ErrResACUInfoTimeoutDTCErrorInfo:0]
          data-element=tec_ComM_ACUInfoTimeoutInfo_Bus, filter=data-filter-type=ALWAYS, init-value=fields=[ComM_MonStatACUInfoTimeoutInfo:0, ComM_MonResACUInfoTimeoutInfo:0, ComM_ErrStatACUInfoTimeoutInfo:0, ComM_ErrResACUInfoTimeoutInfo:0]
          data-element=tec_ComM_ACUInfoCRCDTCInfo_Bus, init-value=fields=[ComM_MonStatACUInfoCRCDTCErrorInfo:0, ComM_MonResACUInfoCRCDTCErrorInfo:0, ComM_ErrStatACUInfoCRCDTCErrorInfo:0, ComM_ErrResACUInfoCRCDTCErrorInfo:0]
      PTCAN_BusoffStatus: nonqueued-receiver-com-spec{data-element=BusoffStatus, filter=data-filter-type=ALWAYS, init-value=0}, required-interface=PTCAN_BusoffStatus
      CHCAN_BusoffStatus: nonqueued-receiver-com-spec{data-element=BusoffStatus, filter=data-filter-type=ALWAYS, init-value=0}, required-interface=CHCAN_BusoffStatus
      RTE_R_LvMgmt_BSBattUDcNorm_Flg: nonqueued-receiver-com-spec{data-element=tec_LvMgmt_BSBattUDcNorm_Flg, filter=data-filter-type=ALWAYS, init-value=0}, required-interface=IF_LvMgmt_BSBattUDcNorm_Flg
      RTE_R_ComM_BCM05MsgErrInfo_Bus: required-interface=IF_ComM_BCM05MsgErrInfo_Bus
        required-com-specs:
          data-element=tec_ComM_BCM05CRCDTCInfo_Bus, filter=data-filter-type=ALWAYS, init-value=fields=[ComM_MonStatBCM05CRCDTCErrorInfo:0, ComM_MonResBCM05CRCDTCErrorInfo:0, ComM_ErrStatBCM05CRCDTCErrorInfo:0, ComM_ErrResBCM05CRCDTCErrorInfo:0]
          data-element=tec_ComM_BCM05TimeoutDTCInfo_Bus, filter=data-filter-type=ALWAYS, init-value=fields=[ComM_MonStatBCM05TimeoutDTCErrorInfo:0, ComM_MonResBCM05TimeoutDTCErrorInfo:0, ComM_ErrStatBCM05TimeoutDTCErrorInfo:0, ComM_ErrResBCM05TimeoutDTCErrorInfo:0]
      RTE_R_ComM_DCMFRMsgErrInfo_Bus: required-interface=IF_ComM_DCMFRMsgErrInfo_Bus
        required-com-specs:
          data-element=tec_ComM_DCMFRTimeoutInfo_Bus, filter=data-filter-type=ALWAYS, init-value=fields=[ComM_MonStatDCMFRTimeoutInfo:0, ComM_MonResDCMFRTimeoutInfo:0, ComM_ErrStatDCMFRTimeoutInfo:0, ComM_ErrResDCMFRTimeoutInfo:0]
          data-element=tec_ComM_DCMFRTimeoutDTCInfo_Bus, init-value=fields=[ComM_MonStatDCMFRTimeoutDTCErrorInfo:0, ComM_MonResDCMFRTimeoutDTCErrorInfo:0, ComM_ErrStatDCMFRTimeoutDTCErrorInfo:0, ComM_ErrResDCMFRTimeoutDTCErrorInfo:0]
      RTE_R_ComM_DCMRRMsgErrInfo_Bus: required-interface=IF_ComM_DCMRRMsgErrInfo_Bus
        required-com-specs:
          data-element=tec_ComM_DCMRRTimeoutInfo_Bus, filter=data-filter-type=ALWAYS, init-value=fields=[ComM_MonStatDCMRRTimeoutInfo:0, ComM_MonResDCMRRTimeoutInfo:0, ComM_ErrStatDCMRRTimeoutInfo:0, ComM_ErrResDCMRRTimeoutInfo:0]
          data-element=tec_ComM_DCMRRTimeoutDTCInfo_Bus, init-value=fields=[ComM_MonStatDCMRRTimeoutDTCErrorInfo:0, ComM_MonResDCMRRTimeoutDTCErrorInfo:0, ComM_ErrStatDCMRRTimeoutDTCErrorInfo:0, ComM_ErrResDCMRRTimeoutDTCErrorInfo:0]
      RTE_R_ComM_DCMRLMsgErrInfo_Bus: required-interface=IF_ComM_DCMRLMsgErrInfo_Bus
        required-com-specs:
          data-element=tec_ComM_DCMRLTimeoutInfo_Bus, filter=data-filter-type=ALWAYS, init-value=fields=[ComM_MonStatDCMRLTimeoutInfo:0, ComM_MonResDCMRLTimeoutInfo:0, ComM_ErrStatDCMRLTimeoutInfo:0, ComM_ErrResDCMRLTimeoutInfo:0]
          data-element=tec_ComM_DCMRLTimeoutDTCInfo_Bus, init-value=fields=[ComM_MonStatDCMRLTimeoutDTCErrorInfo:0, ComM_MonResDCMRLTimeoutDTCErrorInfo:0, ComM_ErrStatDCMRLTimeoutDTCErrorInfo:0, ComM_ErrResDCMRLTimeoutDTCErrorInfo:0]
      RTE_R_DiagApp_DisableDCMReqInfo: nonqueued-receiver-com-spec{data-element=tec_DiagApp_DisableDCMReqInfo, filter=data-filter-type=ALWAYS, init-value=0}, required-interface=IF_DiagApp_DisableDCMReqInfo
      RTE_R_ComM_ADCUAEB01MsgErrInfo_Bus: required-interface=IF_ComM_ADCUAEB01MsgErrInfo_Bus
        required-com-specs:
          data-element=tec_ComM_ADCUAEB01TimeoutDTCInfo_Bus, filter=data-filter-type=ALWAYS, init-value=fields=[ComM_MonStatADCUAEB01TimeoutDTCErrorInfo:0, ComM_MonResADCUAEB01TimeoutDTCErrorInfo:0, ComM_ErrStatADCUAEB01TimeoutDTCErrorInfo:0, ComM_ErrResADCUAEB01TimeoutDTCErrorInfo:0]
          data-element=tec_ComM_ADCUAEB01CRCDTCInfo_Bus, filter=data-filter-type=ALWAYS, init-value=fields=[ComM_MonStatADCUAEB01CRCDTCErrorInfo:0, ComM_MonResADCUAEB01CRCDTCErrorInfo:0, ComM_ErrStatADCUAEB01CRCDTCErrorInfo:0, ComM_ErrResADCUAEB01CRCDTCErrorInfo:0]
      RTE_R_ComM_ADCUDAMsgErrInfo_Bus: required-interface=IF_ComM_ADCUDAMsgErrInfo_Bus
        required-com-specs:
          data-element=tec_ComM_ADCUDATimeoutDTCInfo_Bus, filter=data-filter-type=ALWAYS, init-value=fields=[ComM_MonStatADCUDATimeoutDTCErrorInfo:0, ComM_MonResADCUDATimeoutDTCErrorInfo:0, ComM_ErrStatADCUDATimeoutDTCErrorInfo:0, ComM_ErrResADCUDATimeoutDTCErrorInfo:0]
          data-element=tec_ComM_ADCUDACRCDTCInfo_Bus, filter=data-filter-type=ALWAYS, init-value=fields=[ComM_MonStatADCUDACRCDTCErrorInfo:0, ComM_MonResADCUDACRCDTCErrorInfo:0, ComM_ErrStatADCUDACRCDTCErrorInfo:0, ComM_ErrResADCUDACRCDTCErrorInfo:0]
      RTE_R_ComM_ADCUAPS01MsgErrInfo_Bus: required-interface=IF_ComM_ADCUAPS01MsgErrInfo_Bus
        required-com-specs:
          data-element=tec_ComM_ADCUAPS01TimeoutDTCInfo_Bus, filter=data-filter-type=ALWAYS, init-value=fields=[ComM_MonStatADCUAPS01TimeoutDTCErrorInfo:0, ComM_MonResADCUAPS01TimeoutDTCErrorInfo:0, ComM_ErrStatADCUAPS01TimeoutDTCErrorInfo:0, ComM_ErrResADCUAPS01TimeoutDTCErrorInfo:0]
          data-element=tec_ComM_ADCUAPS01CRCDTCInfo_Bus, filter=data-filter-type=ALWAYS, init-value=fields=[ComM_MonStatADCUAPS01CRCDTCErrorInfo:0, ComM_MonResADCUAPS01CRCDTCErrorInfo:0, ComM_ErrStatADCUAPS01CRCDTCErrorInfo:0, ComM_ErrResADCUAPS01CRCDTCErrorInfo:0]
      RTE_R_ComM_SGW16MsgErrInfo_Bus: required-interface=IF_ComM_SGW16MsgErrInfo_Bus
        required-com-specs:
          data-element=tec_ComM_SGW16TimeoutInfo_Bus, filter=data-filter-type=ALWAYS, init-value=fields=[ComM_MonStatSGW16TimeoutInfo:0, ComM_MonResSGW16TimeoutInfo:0, ComM_ErrStatSGW16TimeoutInfo:0, ComM_ErrResSGW16TimeoutInfo:0]
          data-element=tec_ComM_SGW16TimeoutDTCInfo_Bus, filter=data-filter-type=ALWAYS, init-value=fields=[ComM_MonStatSGW16TimeoutDTCErrorInfo:0, ComM_MonResSGW16TimeoutDTCErrorInfo:0, ComM_ErrStatSGW16CTimeoutDTCErrorInfo:0, ComM_ErrResSGW16TimeoutDTCErrorInfo:0]
      RTE_R_ComM_IBSAPSMsgErrInfo_Bus: required-interface=IF_ComM_IBSAPSMsgErrInfo_Bus
        required-com-specs:
          data-element=tec_ComM_IBSAPSTimeoutDTCInfo_Bus, filter=data-filter-type=ALWAYS, init-value=fields=[ComM_MonStatIBSAPSTimeoutDTCErrorInfo:0, ComM_MonResIBSAPSTimeoutDTCErrorInfo:0, ComM_ErrStatIBSAPSTimeoutDTCErrorInfo:0, ComM_ErrResIBSAPSTimeoutDTCErrorInfo:0]
          data-element=tec_ComM_IBSAPSCRCDTCInfo_Bus, filter=data-filter-type=ALWAYS, init-value=fields=[ComM_MonStatIBSAPSCRCDTCErrorInfo:0, ComM_MonResIBSAPSCRCDTCErrorInfo:0, ComM_ErrStatIBSAPSCRCDTCErrorInfo:0, ComM_ErrResIBSAPSCRCDTCErrorInfo:0]
      RTE_R_ComM_SGW17MsgErrInfo_Bus: required-interface=IF_ComM_SGW17MsgErrInfo_Bus
        required-com-specs:
          data-element=tec_ComM_SGW17TimeoutDTCInfo_Bus, filter=data-filter-type=ALWAYS, init-value=fields=[ComM_MonStatSGW17TimeoutDTCErrorInfo:0, ComM_MonResSGW17TimeoutDTCErrorInfo:0, ComM_ErrStatSGW17TimeoutDTCErrorInfo:0, ComM_ErrResSGW17TimeoutDTCErrorInfo:0]
          data-element=tec_ComM_SGW17TimeoutInfo_Bus, filter=data-filter-type=ALWAYS, init-value=fields=[ComM_MonStatSGW17TimeoutInfo:0, ComM_MonResSGW17TimeoutInfo:0, ComM_ErrStatSGW17TimeoutInfo:0, ComM_ErrResSGW17TimeoutInfo:0]
      RTE_R_DCCAN_BusoffStatus_BusoffStatus: nonqueued-receiver-com-spec{data-element=BusoffStatus, filter=data-filter-type=ALWAYS, init-value=0}, required-interface=DCCAN_BusoffStatus
    behavior CtAp_ComMErr_InternalBehavior
      timing event TMT_R_ComMErr_Cyclic_10ms: start-on-event=R_ComMErr_Cyclic_10ms, period=0.01
      init event CtAp_ComMErr_InitEvent: start-on-event=R_ComMErr_Init
      runnable R_ComMErr_Cyclic_10ms
        data-receive-point-by-arguments:
          101 x access:
            REC_RTE_R_ComM_ACU01MsgErrInfo_Bus_tec_ComM_ACU01CRCDTCInfo_Bus: accessed-variable=RTE_R_ComM_ACU01MsgErrInfo_Bus.tec_ComM_ACU01CRCDTCInfo_Bus
            REC_RTE_R_ComM_ACU01MsgErrInfo_Bus_tec_ComM_ACU01TimeoutDTCInfo_Bus: accessed-variable=RTE_R_ComM_ACU01MsgErrInfo_Bus.tec_ComM_ACU01TimeoutDTCInfo_Bus
            REC_RTE_R_ComM_ACU02MsgErrInfo_Bus_tec_ComM_ACU02CRCDTCInfo_Bus: accessed-variable=RTE_R_ComM_ACU02MsgErrInfo_Bus.tec_ComM_ACU02CRCDTCInfo_Bus
            REC_RTE_R_ComM_ACU02MsgErrInfo_Bus_tec_ComM_ACU02TimeoutDTCInfo_Bus: accessed-variable=RTE_R_ComM_ACU02MsgErrInfo_Bus.tec_ComM_ACU02TimeoutDTCInfo_Bus
            REC_RTE_R_ComM_ADCUACC02MsgErrInfo_Bus_tec_ComM_ADCUACC02CRCDTCInfo_Bus: accessed-variable=RTE_R_ComM_ADCUACC02MsgErrInfo_Bus.tec_ComM_ADCUACC02CRCDTCInfo_Bus
            REC_RTE_R_ComM_ADCUACC02MsgErrInfo_Bus_tec_ComM_ADCUACC02TimeoutDTCInfo_Bus: accessed-variable=RTE_R_ComM_ADCUACC02MsgErrInfo_Bus.tec_ComM_ADCUACC02TimeoutDTCInfo_Bus
            REC_RTE_R_ComM_ADCUACC02MsgErrInfo_Bus_tec_ComM_ADCUACC02TimeoutInfo_Bus: accessed-variable=RTE_R_ComM_ADCUACC02MsgErrInfo_Bus.tec_ComM_ADCUACC02TimeoutInfo_Bus
            REC_RTE_R_ComM_ADCUBodyReqMsgErrInfo_Bus_tec_ComM_ADCUBodyReqCRCDTCInfo_Bus: accessed-variable=RTE_R_ComM_ADCUBodyReqMsgErrInfo_Bus.tec_ComM_ADCUBodyReqCRCDTCInfo_Bus
            REC_RTE_R_ComM_ADCUBodyReqMsgErrInfo_Bus_tec_ComM_ADCUBodyReqTimeoutDTCInfo_Bus: accessed-variable=RTE_R_ComM_ADCUBodyReqMsgErrInfo_Bus.tec_ComM_ADCUBodyReqTimeoutDTCInfo_Bus
            REC_RTE_R_ComM_APTCTCUMsgErrInfo_Bus_tec_ComM_APTCTCUTimeoutDTCInfo_Bus: accessed-variable=RTE_R_ComM_APTCTCUMsgErrInfo_Bus.tec_ComM_APTCTCUTimeoutDTCInfo_Bus
            REC_RTE_R_ComM_APTCTCUMsgErrInfo_Bus_tec_ComM_APTCTCUTimeoutInfo_Bus: accessed-variable=RTE_R_ComM_APTCTCUMsgErrInfo_Bus.tec_ComM_APTCTCUTimeoutInfo_Bus
            REC_RTE_R_ComM_BCM06MsgErrInfo_Bus_tec_ComM_BCM06CRCDTCInfo_Bus: accessed-variable=RTE_R_ComM_BCM06MsgErrInfo_Bus.tec_ComM_BCM06CRCDTCInfo_Bus
            REC_RTE_R_ComM_BCM06MsgErrInfo_Bus_tec_ComM_BCM06TimeoutDTCInfo_Bus: accessed-variable=RTE_R_ComM_BCM06MsgErrInfo_Bus.tec_ComM_BCM06TimeoutDTCInfo_Bus
            REC_RTE_R_ComM_BCM06MsgErrInfo_Bus_tec_ComM_BCM06TimeoutInfo_Bus: accessed-variable=RTE_R_ComM_BCM06MsgErrInfo_Bus.tec_ComM_BCM06TimeoutInfo_Bus
            REC_RTE_R_ComM_BMSErrInfoTimeoutInfo_Bus_tec_ComM_BMSErrInfoTimeoutInfo_Bus: accessed-variable=RTE_R_ComM_BMSErrInfoTimeoutInfo_Bus.tec_ComM_BMSErrInfoTimeoutInfo_Bus
            REC_RTE_R_ComM_BMSSts01ErrInfo_Bus_tec_ComM_BMSSts01CRCDTCInfo_Bus: accessed-variable=RTE_R_ComM_BMSSts01ErrInfo_Bus.tec_ComM_BMSSts01CRCDTCInfo_Bus
            REC_RTE_R_ComM_BMSSts01ErrInfo_Bus_tec_ComM_BMSSts01TimeoutDTCInfo_Bus: accessed-variable=RTE_R_ComM_BMSSts01ErrInfo_Bus.tec_ComM_BMSSts01TimeoutDTCInfo_Bus
            REC_RTE_R_ComM_BMSSts01ErrInfo_Bus_tec_ComM_BMSSts01TimeoutInfo_Bus: accessed-variable=RTE_R_ComM_BMSSts01ErrInfo_Bus.tec_ComM_BMSSts01TimeoutInfo_Bus
            REC_RTE_R_ComM_BMSSts02MsgErrInfo_Bus_tec_ComM_BMSSts02TimeoutDTCInfo_Bus: accessed-variable=RTE_R_ComM_BMSSts02MsgErrInfo_Bus.tec_ComM_BMSSts02TimeoutDTCInfo_Bus
            REC_RTE_R_ComM_BMSSts02MsgErrInfo_Bus_tec_ComM_BMSSts02TimeoutInfo_Bus: accessed-variable=RTE_R_ComM_BMSSts02MsgErrInfo_Bus.tec_ComM_BMSSts02TimeoutInfo_Bus
            REC_RTE_R_ComM_CGW01MsgErrInfo_Bus_tec_ComM_CGW01TimeoutDTCInfo_Bus: accessed-variable=RTE_R_ComM_CGW01MsgErrInfo_Bus.tec_ComM_CGW01TimeoutDTCInfo_Bus
            REC_RTE_R_ComM_CGW01MsgErrInfo_Bus_tec_ComM_CGW01TimeoutInfo_Bus: accessed-variable=RTE_R_ComM_CGW01MsgErrInfo_Bus.tec_ComM_CGW01TimeoutInfo_Bus
            REC_RTE_R_ComM_DCMFL02MsgErrInfo_Bus_tec_ComM_DCMFL02CRCDTCInfo_Bus: accessed-variable=RTE_R_ComM_DCMFL02MsgErrInfo_Bus.tec_ComM_DCMFL02CRCDTCInfo_Bus
            REC_RTE_R_ComM_DCMFL02MsgErrInfo_Bus_tec_ComM_DCMFL02TimeoutDTCInfo_Bus: accessed-variable=RTE_R_ComM_DCMFL02MsgErrInfo_Bus.tec_ComM_DCMFL02TimeoutDTCInfo_Bus
            REC_RTE_R_ComM_DCMFL02MsgErrInfo_Bus_tec_ComM_DCMFL02TimeoutInfo_Bus: accessed-variable=RTE_R_ComM_DCMFL02MsgErrInfo_Bus.tec_ComM_DCMFL02TimeoutInfo_Bus
            REC_RTE_R_ComM_EVCOMSts01MsgErrInfo_Bus_tec_ComM_EVCOMSts01TimeoutDTCInfo_Bus: accessed-variable=RTE_R_ComM_EVCOMSts01MsgErrInfo_Bus.tec_ComM_EVCOMSts01TimeoutDTCInfo_Bus
            REC_RTE_R_ComM_EVCOMSts01MsgErrInfo_Bus_tec_ComM_EVCOMSts01TimeoutInfo_Bus: accessed-variable=RTE_R_ComM_EVCOMSts01MsgErrInfo_Bus.tec_ComM_EVCOMSts01TimeoutInfo_Bus
            REC_RTE_R_ComM_IBSACCMsgErrInfo_Bus_tec_ComM_IBSACCCRCDTCInfo_Bus: accessed-variable=RTE_R_ComM_IBSACCMsgErrInfo_Bus.tec_ComM_IBSACCCRCDTCInfo_Bus
            REC_RTE_R_ComM_IBSACCMsgErrInfo_Bus_tec_ComM_IBSACCTimeoutDTCInfo_Bus: accessed-variable=RTE_R_ComM_IBSACCMsgErrInfo_Bus.tec_ComM_IBSACCTimeoutDTCInfo_Bus
            REC_RTE_R_ComM_IBSSts01MsgErrInfo_Bus_tec_ComM_IBSSts01CRCDTCInfo_Bus: accessed-variable=RTE_R_ComM_IBSSts01MsgErrInfo_Bus.tec_ComM_IBSSts01CRCDTCInfo_Bus
            REC_RTE_R_ComM_IBSSts01MsgErrInfo_Bus_tec_ComM_IBSSts01TimeoutDTCInfo_Bus: accessed-variable=RTE_R_ComM_IBSSts01MsgErrInfo_Bus.tec_ComM_IBSSts01TimeoutDTCInfo_Bus
            REC_RTE_R_ComM_IBSSts02MsgErrInfo_Bus_tec_ComM_IBSSts02CRCDTCInfo_Bus: accessed-variable=RTE_R_ComM_IBSSts02MsgErrInfo_Bus.tec_ComM_IBSSts02CRCDTCInfo_Bus
            REC_RTE_R_ComM_IBSSts02MsgErrInfo_Bus_tec_ComM_IBSSts02TimeoutDTCInfo_Bus: accessed-variable=RTE_R_ComM_IBSSts02MsgErrInfo_Bus.tec_ComM_IBSSts02TimeoutDTCInfo_Bus
            REC_RTE_R_ComM_IBSSts03MsgErrInfo_Bus_tec_ComM_IBSSts03CRCDTCInfo_Bus: accessed-variable=RTE_R_ComM_IBSSts03MsgErrInfo_Bus.tec_ComM_IBSSts03CRCDTCInfo_Bus
            REC_RTE_R_ComM_IBSSts03MsgErrInfo_Bus_tec_ComM_IBSSts03TimeoutDTCInfo_Bus: accessed-variable=RTE_R_ComM_IBSSts03MsgErrInfo_Bus.tec_ComM_IBSSts03TimeoutDTCInfo_Bus
            REC_RTE_R_ComM_IBSSts04MsgErrInfo_Bus_tec_ComM_IBSSts04CRCDTCInfo_Bus: accessed-variable=RTE_R_ComM_IBSSts04MsgErrInfo_Bus.tec_ComM_IBSSts04CRCDTCInfo_Bus
            REC_RTE_R_ComM_IBSSts04MsgErrInfo_Bus_tec_ComM_IBSSts04TimeoutDTCInfo_Bus: accessed-variable=RTE_R_ComM_IBSSts04MsgErrInfo_Bus.tec_ComM_IBSSts04TimeoutDTCInfo_Bus
            REC_RTE_R_ComM_IBSSts05MsgErrInfo_Bus_tec_ComM_IBSSts05CRCDTCInfo_Bus: accessed-variable=RTE_R_ComM_IBSSts05MsgErrInfo_Bus.tec_ComM_IBSSts05CRCDTCInfo_Bus
            REC_RTE_R_ComM_IBSSts05MsgErrInfo_Bus_tec_ComM_IBSSts05TimeoutDTCInfo_Bus: accessed-variable=RTE_R_ComM_IBSSts05MsgErrInfo_Bus.tec_ComM_IBSSts05TimeoutDTCInfo_Bus
            REC_RTE_R_ComM_IBSSts05MsgErrInfo_Bus_tec_ComM_IBSSts05TimeoutInfo_Bus: accessed-variable=RTE_R_ComM_IBSSts05MsgErrInfo_Bus.tec_ComM_IBSSts05TimeoutInfo_Bus
            REC_RTE_R_ComM_IBSSts06MsgErrInfo_Bus_tec_ComM_IBSSts06CRCDTCInfo_Bus: accessed-variable=RTE_R_ComM_IBSSts06MsgErrInfo_Bus.tec_ComM_IBSSts06CRCDTCInfo_Bus
            REC_RTE_R_ComM_IBSSts06MsgErrInfo_Bus_tec_ComM_IBSSts06TimeoutDTCInfo_Bus: accessed-variable=RTE_R_ComM_IBSSts06MsgErrInfo_Bus.tec_ComM_IBSSts06TimeoutDTCInfo_Bus
            REC_RTE_R_ComM_IBSTqMsgErrInfo_Bus_tec_ComM_IBSTqCRCDTCInfo_Bus: accessed-variable=RTE_R_ComM_IBSTqMsgErrInfo_Bus.tec_ComM_IBSTqCRCDTCInfo_Bus
            REC_RTE_R_ComM_IBSTqMsgErrInfo_Bus_tec_ComM_IBSTqTimeoutDTCInfo_Bus: accessed-variable=RTE_R_ComM_IBSTqMsgErrInfo_Bus.tec_ComM_IBSTqTimeoutDTCInfo_Bus
            REC_RTE_R_ComM_IBSVCUMotCtrlMsgErrInfo_Bus_tec_ComM_IBSVCUMotCtrlCRCDTCInfo_Bus: accessed-variable=RTE_R_ComM_IBSVCUMotCtrlMsgErrInfo_Bus.tec_ComM_IBSVCUMotCtrlCRCDTCInfo_Bus
            REC_RTE_R_ComM_IBSVCUMotCtrlMsgErrInfo_Bus_tec_ComM_IBSVCUMotCtrlTimeoutDTCInfo_Bus: accessed-variable=RTE_R_ComM_IBSVCUMotCtrlMsgErrInfo_Bus.tec_ComM_IBSVCUMotCtrlTimeoutDTCInfo_Bus
            REC_RTE_R_ComM_IBSVCUMotCtrlMsgErrInfo_Bus_tec_ComM_IBSVCUMotCtrlTimeoutInfo_Bus: accessed-variable=RTE_R_ComM_IBSVCUMotCtrlMsgErrInfo_Bus.tec_ComM_IBSVCUMotCtrlTimeoutInfo_Bus
            REC_RTE_R_ComM_IBSWhlSpd01MsgErrInfo_Bus_tec_ComM_IBSWhlSpd01CRCDTCInfo_Bus: accessed-variable=RTE_R_ComM_IBSWhlSpd01MsgErrInfo_Bus.tec_ComM_IBSWhlSpd01CRCDTCInfo_Bus
            REC_RTE_R_ComM_IBSWhlSpd01MsgErrInfo_Bus_tec_ComM_IBSWhlSpd01TimeoutDTCInfo_Bus: accessed-variable=RTE_R_ComM_IBSWhlSpd01MsgErrInfo_Bus.tec_ComM_IBSWhlSpd01TimeoutDTCInfo_Bus
            REC_RTE_R_ComM_IBSWhlSpd02MsgErrInfo_Bus_tec_ComM_IBSWhlSpd02CRCDTCInfo_Bus: accessed-variable=RTE_R_ComM_IBSWhlSpd02MsgErrInfo_Bus.tec_ComM_IBSWhlSpd02CRCDTCInfo_Bus
            REC_RTE_R_ComM_IBSWhlSpd02MsgErrInfo_Bus_tec_ComM_IBSWhlSpd02TimeoutDTCInfo_Bus: accessed-variable=RTE_R_ComM_IBSWhlSpd02MsgErrInfo_Bus.tec_ComM_IBSWhlSpd02TimeoutDTCInfo_Bus
            REC_RTE_R_ComM_MCU01MsgErrInfo_Bus_tec_ComM_MCU01CRCDTCInfo_Bus: accessed-variable=RTE_R_ComM_MCU01MsgErrInfo_Bus.tec_ComM_MCU01CRCDTCInfo_Bus
            REC_RTE_R_ComM_MCU01MsgErrInfo_Bus_tec_ComM_MCU01TimeoutDTCInfo_Bus: accessed-variable=RTE_R_ComM_MCU01MsgErrInfo_Bus.tec_ComM_MCU01TimeoutDTCInfo_Bus
            REC_RTE_R_ComM_MCU01MsgErrInfo_Bus_tec_ComM_MCU01TimeoutInfo_Bus: accessed-variable=RTE_R_ComM_MCU01MsgErrInfo_Bus.tec_ComM_MCU01TimeoutInfo_Bus
            REC_RTE_R_ComM_MCUFailrCodMsgErrInfo_Bus_tec_ComM_MCUFailrCodCRCDTCInfo_Bus: accessed-variable=RTE_R_ComM_MCUFailrCodMsgErrInfo_Bus.tec_ComM_MCUFailrCodCRCDTCInfo_Bus
            REC_RTE_R_ComM_MCUFailrCodMsgErrInfo_Bus_tec_ComM_MCUFailrCodTimeoutDTCInfo_Bus: accessed-variable=RTE_R_ComM_MCUFailrCodMsgErrInfo_Bus.tec_ComM_MCUFailrCodTimeoutDTCInfo_Bus
            REC_RTE_R_ComM_PODDCDC01MsgErrInfo_Bus_tec_ComM_PODDCDC01TimeoutDTCInfo_Bus: accessed-variable=RTE_R_ComM_PODDCDC01MsgErrInfo_Bus.tec_ComM_PODDCDC01TimeoutDTCInfo_Bus
            REC_RTE_R_ComM_PODDCDC01MsgErrInfo_Bus_tec_ComM_PODDCDC01TimeoutInfo_Bus: accessed-variable=RTE_R_ComM_PODDCDC01MsgErrInfo_Bus.tec_ComM_PODDCDC01TimeoutInfo_Bus
            REC_RTE_R_ComM_PODOBCChrgStatMsgErrInfo_Bus_tec_ComM_PODOBCChrgStatTimeoutDTCInfo_Bus: accessed-variable=RTE_R_ComM_PODOBCChrgStatMsgErrInfo_Bus.tec_ComM_PODOBCChrgStatTimeoutDTCInfo_Bus
            REC_RTE_R_ComM_PODOBCChrgStatMsgErrInfo_Bus_tec_ComM_PODOBCChrgStatTimeoutInfo_Bus: accessed-variable=RTE_R_ComM_PODOBCChrgStatMsgErrInfo_Bus.tec_ComM_PODOBCChrgStatTimeoutInfo_Bus
            REC_RTE_R_ComM_PODSts01TimeoutInfo_Bus_tec_ComM_PODSts01TimeoutInfo_Bus: accessed-variable=RTE_R_ComM_PODSts01TimeoutInfo_Bus.tec_ComM_PODSts01TimeoutInfo_Bus
            REC_RTE_R_ComM_PRNDMsgErrInfo_Bus_tec_ComM_PRNDCRCDTCInfo_Bus: accessed-variable=RTE_R_ComM_PRNDMsgErrInfo_Bus.tec_ComM_PRNDCRCDTCInfo_Bus
            REC_RTE_R_ComM_PRNDMsgErrInfo_Bus_tec_ComM_PRNDTimeoutDTCInfo_Bus: accessed-variable=RTE_R_ComM_PRNDMsgErrInfo_Bus.tec_ComM_PRNDTimeoutDTCInfo_Bus
            REC_RTE_R_ComM_PRNDMsgErrInfo_Bus_tec_ComM_PRNDTimeoutInfo_Bus: accessed-variable=RTE_R_ComM_PRNDMsgErrInfo_Bus.tec_ComM_PRNDTimeoutInfo_Bus
            REC_RTE_R_ComM_SGWPT01MsgErrInfo_Bus_tec_ComM_SGWPT01TimeoutDTCInfo_Bus: accessed-variable=RTE_R_ComM_SGWPT01MsgErrInfo_Bus.tec_ComM_SGWPT01TimeoutDTCInfo_Bus
            REC_RTE_R_ComM_SGWPT01MsgErrInfo_Bus_tec_ComM_SGWPT01TimeoutInfo_Bus: accessed-variable=RTE_R_ComM_SGWPT01MsgErrInfo_Bus.tec_ComM_SGWPT01TimeoutInfo_Bus
            REC_RTE_R_ComM_SGWTimMsgErrInfo_Bus_tec_ComM_SGWTimTimeoutDTCInfo_Bus: accessed-variable=RTE_R_ComM_SGWTimMsgErrInfo_Bus.tec_ComM_SGWTimTimeoutDTCInfo_Bus
            REC_RTE_R_ComM_SGWTimMsgErrInfo_Bus_tec_ComM_SGWTimTimeoutInfo_Bus: accessed-variable=RTE_R_ComM_SGWTimMsgErrInfo_Bus.tec_ComM_SGWTimTimeoutInfo_Bus
            REC_RTE_R_ComM_TCU01MsgErrInfo_Bus_tec_ComM_TCU01TimeoutDTCInfo_Bus: accessed-variable=RTE_R_ComM_TCU01MsgErrInfo_Bus.tec_ComM_TCU01TimeoutDTCInfo_Bus
            REC_RTE_R_ComM_TCU01MsgErrInfo_Bus_tec_ComM_TCU01TimeoutInfo_Bus: accessed-variable=RTE_R_ComM_TCU01MsgErrInfo_Bus.tec_ComM_TCU01TimeoutInfo_Bus
            REC_RTE_R_ComM_ACUInfoMsgErrInfo_Bus_tec_ComM_ACUInfoTimeoutDTCInfo_Bus: accessed-variable=RTE_R_ComM_ACUInfoMsgErrInfo_Bus.tec_ComM_ACUInfoTimeoutDTCInfo_Bus
            REC_RTE_R_ComM_ACUInfoMsgErrInfo_Bus_tec_ComM_ACUInfoTimeoutInfo_Bus: accessed-variable=RTE_R_ComM_ACUInfoMsgErrInfo_Bus.tec_ComM_ACUInfoTimeoutInfo_Bus
            REC_CHCAN_BusoffStatus_BusoffStatus: accessed-variable=CHCAN_BusoffStatus.BusoffStatus
            REC_PTCAN_BusoffStatus_BusoffStatus: accessed-variable=PTCAN_BusoffStatus.BusoffStatus
            REC_RTE_R_LvMgmt_BSBattUDcNorm_Flg_tec_LvMgmt_BSBattUDcNorm_Flg: accessed-variable=RTE_R_LvMgmt_BSBattUDcNorm_Flg.tec_LvMgmt_BSBattUDcNorm_Flg
            REC_RTE_R_ComM_MCUFailrCodMsgErrInfo_Bus_tec_ComM_MCUFailrCodCRCInfo_Bus: accessed-variable=RTE_R_ComM_MCUFailrCodMsgErrInfo_Bus.tec_ComM_MCUFailrCodCRCInfo_Bus
            REC_RTE_R_ComM_MCUFailrCodMsgErrInfo_Bus_tec_ComM_MCUFailrCodE2ETimeoutInfo_Bus: accessed-variable=RTE_R_ComM_MCUFailrCodMsgErrInfo_Bus.tec_ComM_MCUFailrCodE2ETimeoutInfo_Bus
            REC_RTE_R_ComM_BCM05MsgErrInfo_Bus_tec_ComM_BCM05CRCDTCInfo_Bus: accessed-variable=RTE_R_ComM_BCM05MsgErrInfo_Bus.tec_ComM_BCM05CRCDTCInfo_Bus
            REC_RTE_R_ComM_BCM05MsgErrInfo_Bus_tec_ComM_BCM05TimeoutDTCInfo_Bus: accessed-variable=RTE_R_ComM_BCM05MsgErrInfo_Bus.tec_ComM_BCM05TimeoutDTCInfo_Bus
            REC_RTE_R_ComM_DCMFRMsgErrInfo_Bus_tec_ComM_DCMFRTimeoutInfo_Bus: accessed-variable=RTE_R_ComM_DCMFRMsgErrInfo_Bus.tec_ComM_DCMFRTimeoutInfo_Bus
            REC_RTE_R_ComM_DCMRLMsgErrInfo_Bus_tec_ComM_DCMRLTimeoutInfo_Bus: accessed-variable=RTE_R_ComM_DCMRLMsgErrInfo_Bus.tec_ComM_DCMRLTimeoutInfo_Bus
            REC_RTE_R_ComM_DCMRRMsgErrInfo_Bus_tec_ComM_DCMRRTimeoutInfo_Bus: accessed-variable=RTE_R_ComM_DCMRRMsgErrInfo_Bus.tec_ComM_DCMRRTimeoutInfo_Bus
            REC_RTE_R_DiagApp_DisableDCMReqInfo_tec_DiagApp_DisableDCMReqInfo: accessed-variable=RTE_R_DiagApp_DisableDCMReqInfo.tec_DiagApp_DisableDCMReqInfo
            REC_RTE_R_ComM_ADCUAEB01MsgErrInfo_Bus_tec_ComM_ADCUAEB01CRCDTCInfo_Bus: accessed-variable=RTE_R_ComM_ADCUAEB01MsgErrInfo_Bus.tec_ComM_ADCUAEB01CRCDTCInfo_Bus
            REC_RTE_R_ComM_ADCUAEB01MsgErrInfo_Bus_tec_ComM_ADCUAEB01TimeoutDTCInfo_Bus: accessed-variable=RTE_R_ComM_ADCUAEB01MsgErrInfo_Bus.tec_ComM_ADCUAEB01TimeoutDTCInfo_Bus
            REC_RTE_R_ComM_ADCUAPS01MsgErrInfo_Bus_tec_ComM_ADCUAPS01CRCDTCInfo_Bus: accessed-variable=RTE_R_ComM_ADCUAPS01MsgErrInfo_Bus.tec_ComM_ADCUAPS01CRCDTCInfo_Bus
            REC_RTE_R_ComM_ADCUAPS01MsgErrInfo_Bus_tec_ComM_ADCUAPS01TimeoutDTCInfo_Bus: accessed-variable=RTE_R_ComM_ADCUAPS01MsgErrInfo_Bus.tec_ComM_ADCUAPS01TimeoutDTCInfo_Bus
            REC_RTE_R_ComM_ADCUDAMsgErrInfo_Bus_tec_ComM_ADCUDACRCDTCInfo_Bus: accessed-variable=RTE_R_ComM_ADCUDAMsgErrInfo_Bus.tec_ComM_ADCUDACRCDTCInfo_Bus
            REC_RTE_R_ComM_ADCUDAMsgErrInfo_Bus_tec_ComM_ADCUDATimeoutDTCInfo_Bus: accessed-variable=RTE_R_ComM_ADCUDAMsgErrInfo_Bus.tec_ComM_ADCUDATimeoutDTCInfo_Bus
            REC_RTE_R_ComM_IBSAPSMsgErrInfo_Bus_tec_ComM_IBSAPSCRCDTCInfo_Bus: accessed-variable=RTE_R_ComM_IBSAPSMsgErrInfo_Bus.tec_ComM_IBSAPSCRCDTCInfo_Bus
            REC_RTE_R_ComM_IBSAPSMsgErrInfo_Bus_tec_ComM_IBSAPSTimeoutDTCInfo_Bus: accessed-variable=RTE_R_ComM_IBSAPSMsgErrInfo_Bus.tec_ComM_IBSAPSTimeoutDTCInfo_Bus
            REC_RTE_R_ComM_SGW16MsgErrInfo_Bus_tec_ComM_SGW16TimeoutDTCInfo_Bus: accessed-variable=RTE_R_ComM_SGW16MsgErrInfo_Bus.tec_ComM_SGW16TimeoutDTCInfo_Bus
            REC_RTE_R_ComM_SGW16MsgErrInfo_Bus_tec_ComM_SGW16TimeoutInfo_Bus: accessed-variable=RTE_R_ComM_SGW16MsgErrInfo_Bus.tec_ComM_SGW16TimeoutInfo_Bus
            REC_RTE_R_ComM_SGW17MsgErrInfo_Bus_tec_ComM_SGW17TimeoutDTCInfo_Bus: accessed-variable=RTE_R_ComM_SGW17MsgErrInfo_Bus.tec_ComM_SGW17TimeoutDTCInfo_Bus
            REC_RTE_R_ComM_SGW17MsgErrInfo_Bus_tec_ComM_SGW17TimeoutInfo_Bus: accessed-variable=RTE_R_ComM_SGW17MsgErrInfo_Bus.tec_ComM_SGW17TimeoutInfo_Bus
            REC_RTE_R_ComM_ACUInfoMsgErrInfo_Bus_tec_ComM_ACUInfoCRCDTCInfo_Bus: accessed-variable=RTE_R_ComM_ACUInfoMsgErrInfo_Bus.tec_ComM_ACUInfoCRCDTCInfo_Bus
            REC_RTE_R_ComM_CGW01MsgErrInfo_Bus_tec_ComM_CGW01CRCDTCInfo_Bus: accessed-variable=RTE_R_ComM_CGW01MsgErrInfo_Bus.tec_ComM_CGW01CRCDTCInfo_Bus
            REC_RTE_R_ComM_DCMFRMsgErrInfo_Bus_tec_ComM_DCMFRTimeoutIDTCnfo_Bus: accessed-variable=RTE_R_ComM_DCMFRMsgErrInfo_Bus.tec_ComM_DCMFRTimeoutDTCInfo_Bus
            REC_RTE_R_ComM_DCMRLMsgErrInfo_Bus_tec_ComM_DCMRLTimeoutIDTCnfo_Bus: accessed-variable=RTE_R_ComM_DCMRLMsgErrInfo_Bus.tec_ComM_DCMRLTimeoutDTCInfo_Bus
            REC_RTE_R_ComM_DCMRRMsgErrInfo_Bus_tec_ComM_DCMRRTimeoutIDTCnfo_Bus: accessed-variable=RTE_R_ComM_DCMRRMsgErrInfo_Bus.tec_ComM_DCMRRTimeoutDTCInfo_Bus
            REC_RTE_R_DCCAN_BusoffStatus_BusoffStatus_BusoffStatus: accessed-variable=RTE_R_DCCAN_BusoffStatus_BusoffStatus.BusoffStatus
        data-send-points:
          49 x access:
            SEND_RTE_P_ComM_CANBusOffInfo_Bus_tec_ComM_CHCANBusOffDTCInfo_Bus: accessed-variable=RTE_P_ComM_CANBusOffInfo_Bus.tec_ComM_CHCANBusOffDTCInfo_Bus
            SEND_RTE_P_ComM_CANBusOffInfo_Bus_tec_ComM_CHCANBusOffInfo_Bus: accessed-variable=RTE_P_ComM_CANBusOffInfo_Bus.tec_ComM_CHCANBusOffInfo_Bus
            SEND_RTE_P_ComM_CANBusOffInfo_Bus_tec_ComM_EPTCANBusOffDTCInfo_Bus: accessed-variable=RTE_P_ComM_CANBusOffInfo_Bus.tec_ComM_EPTCANBusOffDTCInfo_Bus
            SEND_RTE_P_ComM_CANBusOffInfo_Bus_tec_ComM_EPTCANBusOffInfo_Bus: accessed-variable=RTE_P_ComM_CANBusOffInfo_Bus.tec_ComM_EPTCANBusOffInfo_Bus
            SEND_RTE_P_ComM_ComDTCFailr_tec_ComM_ACUComDTCFailr_Flg: accessed-variable=RTE_P_ComM_ComDTCFailr.tec_ComM_ACUComDTCFailr_Flg
            SEND_RTE_P_ComM_ComDTCFailr_tec_ComM_ADCUComDTCFailr_Flg: accessed-variable=RTE_P_ComM_ComDTCFailr.tec_ComM_ADCUComDTCFailr_Flg
            SEND_RTE_P_ComM_ComDTCFailr_tec_ComM_APTCComDTCFailr_Flg: accessed-variable=RTE_P_ComM_ComDTCFailr.tec_ComM_APTCComDTCFailr_Flg
            SEND_RTE_P_ComM_ComDTCFailr_tec_ComM_BCMComDTCFailr_Flg: accessed-variable=RTE_P_ComM_ComDTCFailr.tec_ComM_BCMComDTCFailr_Flg
            SEND_RTE_P_ComM_ComDTCFailr_tec_ComM_BMSComDTCFailr_Flg: accessed-variable=RTE_P_ComM_ComDTCFailr.tec_ComM_BMSComDTCFailr_Flg
            SEND_RTE_P_ComM_ComDTCFailr_tec_ComM_CGWComDTCFailr_Flg: accessed-variable=RTE_P_ComM_ComDTCFailr.tec_ComM_CGWComDTCFailr_Flg
            SEND_RTE_P_ComM_ComDTCFailr_tec_ComM_CHIBSComDTCFailr_Flg: accessed-variable=RTE_P_ComM_ComDTCFailr.tec_ComM_CHIBSComDTCFailr_Flg
            SEND_RTE_P_ComM_ComDTCFailr_tec_ComM_DCDCComDTCFailr_Flg: accessed-variable=RTE_P_ComM_ComDTCFailr.tec_ComM_DCDCComDTCFailr_Flg
            SEND_RTE_P_ComM_ComDTCFailr_tec_ComM_EVCOMComDTCFailr_Flg: accessed-variable=RTE_P_ComM_ComDTCFailr.tec_ComM_EVCOMComDTCFailr_Flg
            SEND_RTE_P_ComM_ComDTCFailr_tec_ComM_IVIComDTCFailr_Flg: accessed-variable=RTE_P_ComM_ComDTCFailr.tec_ComM_IVIComDTCFailr_Flg
            SEND_RTE_P_ComM_ComDTCFailr_tec_ComM_MCUComDTCFailr_Flg: accessed-variable=RTE_P_ComM_ComDTCFailr.tec_ComM_MCUComDTCFailr_Flg
            SEND_RTE_P_ComM_ComDTCFailr_tec_ComM_PRNDComDTCFailr_Flg: accessed-variable=RTE_P_ComM_ComDTCFailr.tec_ComM_PRNDComDTCFailr_Flg
            SEND_RTE_P_ComM_ComDTCFailr_tec_ComM_SGWComDTCFailr_Flg: accessed-variable=RTE_P_ComM_ComDTCFailr.tec_ComM_SGWComDTCFailr_Flg
            SEND_RTE_P_ComM_ComDTCFailr_tec_ComM_TCUComDTCFailr_Flg: accessed-variable=RTE_P_ComM_ComDTCFailr.tec_ComM_TCUComDTCFailr_Flg
            SEND_RTE_P_ComM_NodComFailr_tec_ComM_BCMNodComFailr_Flg: accessed-variable=RTE_P_ComM_NodComFailr.tec_ComM_BCMNodComFailr_Flg
            SEND_RTE_P_ComM_NodComFailr_tec_ComM_BMSNodComFailr_Flg: accessed-variable=RTE_P_ComM_NodComFailr.tec_ComM_BMSNodComFailr_Flg
            SEND_RTE_P_ComM_NodComFailr_tec_ComM_CGWNodComFailr_Flg: accessed-variable=RTE_P_ComM_NodComFailr.tec_ComM_CGWNodComFailr_Flg
            SEND_RTE_P_ComM_NodComFailr_tec_ComM_CHIBSNodComFailr_Flg: accessed-variable=RTE_P_ComM_NodComFailr.tec_ComM_CHIBSNodComFailr_Flg
            SEND_RTE_P_ComM_NodComFailr_tec_ComM_DCDCNodComFailr_Flg: accessed-variable=RTE_P_ComM_NodComFailr.tec_ComM_DCDCNodComFailr_Flg
            SEND_RTE_P_ComM_NodComFailr_tec_ComM_EPTIBSNodComFailr_Flg: accessed-variable=RTE_P_ComM_NodComFailr.tec_ComM_EPTIBSNodComFailr_Flg
            SEND_RTE_P_ComM_NodComFailr_tec_ComM_EVCOMNodComFailr_Flg: accessed-variable=RTE_P_ComM_NodComFailr.tec_ComM_EVCOMNodComFailr_Flg
            SEND_RTE_P_ComM_NodComFailr_tec_ComM_IVINodComFailr_Flg: accessed-variable=RTE_P_ComM_NodComFailr.tec_ComM_IVINodComFailr_Flg
            SEND_RTE_P_ComM_NodComFailr_tec_ComM_MCUNodComFailr_Flg: accessed-variable=RTE_P_ComM_NodComFailr.tec_ComM_MCUNodComFailr_Flg
            SEND_RTE_P_ComM_NodComFailr_tec_ComM_OBCNodComFailr_Flg: accessed-variable=RTE_P_ComM_NodComFailr.tec_ComM_OBCNodComFailr_Flg
            SEND_RTE_P_ComM_NodComFailr_tec_ComM_PRNDNodComFailr_Flg: accessed-variable=RTE_P_ComM_NodComFailr.tec_ComM_PRNDNodComFailr_Flg
            SEND_RTE_P_ComM_NodComFailr_tec_ComM_SGWNodComFailr_Flg: accessed-variable=RTE_P_ComM_NodComFailr.tec_ComM_SGWNodComFailr_Flg
            SEND_RTE_P_ComM_NodComFailr_tec_ComM_TCUNodComFailr_Flg: accessed-variable=RTE_P_ComM_NodComFailr.tec_ComM_TCUNodComFailr_Flg
            SEND_RTE_P_ComM_ComDTCFailr_tec_ComM_EPTIBSComDTCFailr_Flg: accessed-variable=RTE_P_ComM_ComDTCFailr.tec_ComM_EPTIBSComDTCFailr_Flg
            SEND_RTE_P_ComM_ComDTCFailr_tec_ComM_OBCComDTCFailr_Flg: accessed-variable=RTE_P_ComM_ComDTCFailr.tec_ComM_OBCComDTCFailr_Flg
            SEND_RTE_P_ComM_NodComFailr_tec_ComM_ACUNodComFailr_Flg: accessed-variable=RTE_P_ComM_NodComFailr.tec_ComM_ACUNodComFailr_Flg
            SEND_RTE_P_ComM_NodComFailr_tec_ComM_ADCUNodComFailr_Flg: accessed-variable=RTE_P_ComM_NodComFailr.tec_ComM_ADCUNodComFailr_Flg
            SEND_RTE_P_ComM_NodComFailr_tec_ComM_APTCNodComFailr_Flg: accessed-variable=RTE_P_ComM_NodComFailr.tec_ComM_APTCNodComFailr_Flg
            SEND_RTE_P_ComM_NodComFailr_tec_ComM_DCMFLNodComFailr_Flg: accessed-variable=RTE_P_ComM_NodComFailr.tec_ComM_DCMFLNodComFailr_Flg
            SEND_RTE_P_ComM_NodComFailr_tec_ComM_DCMFRNodComFailr_Flg: accessed-variable=RTE_P_ComM_NodComFailr.tec_ComM_DCMFRNodComFailr_Flg
            SEND_RTE_P_ComM_NodComFailr_tec_ComM_DCMRLNodComFailr_Flg: accessed-variable=RTE_P_ComM_NodComFailr.tec_ComM_DCMRLNodComFailr_Flg
            SEND_RTE_P_ComM_NodComFailr_tec_ComM_DCMRRNodComFailr_Flg: accessed-variable=RTE_P_ComM_NodComFailr.tec_ComM_DCMRRNodComFailr_Flg
            SEND_RTE_P_ComM_CANBusOffInfo_Bus_tec_ComM_DCCANBusOffDTCInfo_Bus: accessed-variable=RTE_P_ComM_CANBusOffInfo_Bus.tec_ComM_DCCANBusOffDTCInfo_Bus
            SEND_RTE_P_ComM_CANBusOffInfo_Bus_tec_ComM_DCCANBusOffInfo_Bus: accessed-variable=RTE_P_ComM_CANBusOffInfo_Bus.tec_ComM_DCCANBusOffInfo_Bus
            SEND_RTE_P_ComM_ComDTCFailr_tec_ComM_DCMFLComDTCFailr_Flg: accessed-variable=RTE_P_ComM_ComDTCFailr.tec_ComM_DCMFLComDTCFailr_Flg
            SEND_RTE_P_ComM_ComDTCFailr_tec_ComM_DCMFRComDTCFailr_Flg: accessed-variable=RTE_P_ComM_ComDTCFailr.tec_ComM_DCMFRComDTCFailr_Flg
            SEND_RTE_P_ComM_ComDTCFailr_tec_ComM_DCMRLComDTCFailr_Flg: accessed-variable=RTE_P_ComM_ComDTCFailr.tec_ComM_DCMRLComDTCFailr_Flg
            SEND_RTE_P_ComM_ComDTCFailr_tec_ComM_DCMRRComDTCFailr_Flg: accessed-variable=RTE_P_ComM_ComDTCFailr.tec_ComM_DCMRRComDTCFailr_Flg
            SEND_RTE_P_ComM_ComDTCFailr_tec_ComM_SGWCHComDTCFailr_Flg: accessed-variable=RTE_P_ComM_ComDTCFailr.tec_ComM_SGWCHComDTCFailr_Flg
            SEND_RTE_P_ComM_NodComFailr_tec_ComM_DCMNodComFailr_Flg: accessed-variable=RTE_P_ComM_NodComFailr.tec_ComM_DCMNodComFailr_Flg
            SEND_RTE_P_ComM_NodComFailr_tec_ComM_SGWCHNodComFailr_Flg: accessed-variable=RTE_P_ComM_NodComFailr.tec_ComM_SGWCHNodComFailr_Flg
      runnable R_ComMErr_Init
  swc implementation CtAp_ComMErr_Implementation: behavior=CtAp_ComMErr_InternalBehavior
